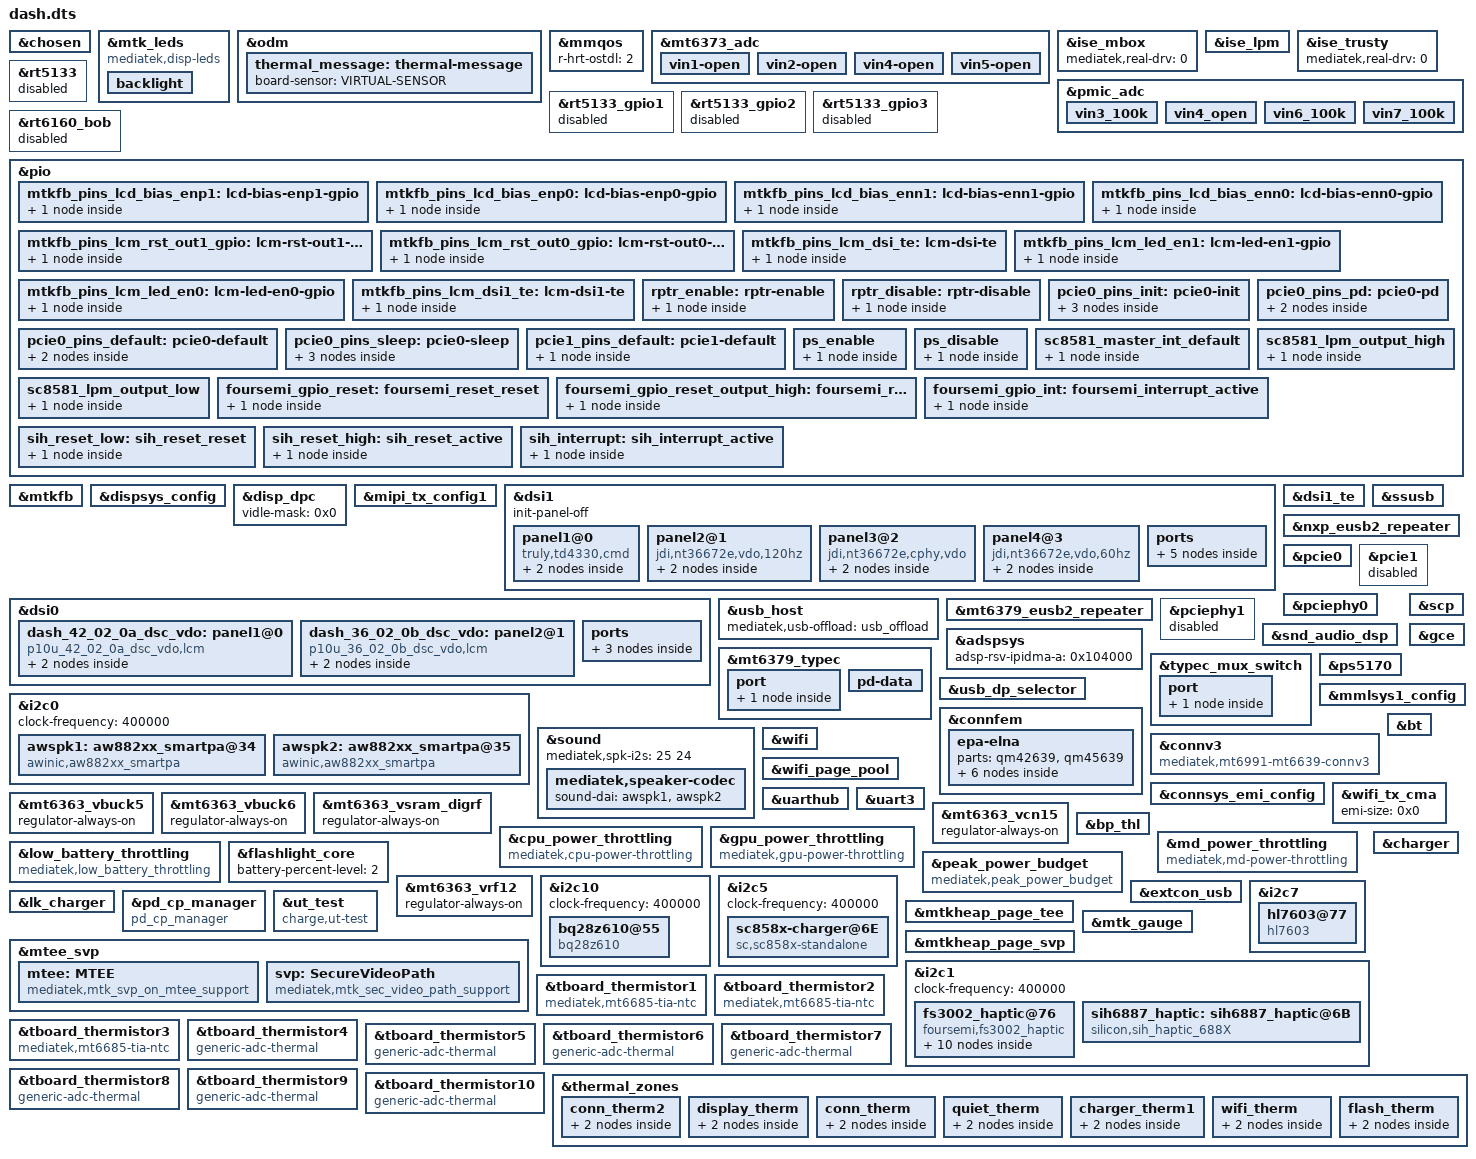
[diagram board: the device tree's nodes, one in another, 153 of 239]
// SPDX-License-Identifier: (GPL-2.0 OR MIT)
/*
 * Copyright (C) 2022 MediaTek Inc.
 */
/dts-v1/;
/plugin/;
#include <dt-bindings/clock/mt6991-clk.h>
#include <dt-bindings/interrupt-controller/arm-gic.h>
#include <dt-bindings/interrupt-controller/irq.h>
#include <dt-bindings/phy/phy.h>
#include <dt-bindings/pinctrl/mt6991-pinfunc.h>
#include <dt-bindings/power/mt6991-power.h>
#include "mediatek/dash-mt6991-common.dtsi"
#include <dt-bindings/iio/mt635x-auxadc.h>
#include <dt-bindings/thermal/thermal.h>
#include <dt-bindings/gce/mt6991-gce.h>
#include "mediatek/dash-sensor-common.dtsi"
#include "mediatek/cust_mt6991_nfc_nxp_dash.dtsi"
#include "mediatek/xiaomi_dash_t1_chip.dtsi"

&chosen {
bootargs_ext = "cpufreq.default_governor=conservative \
		rcu_nocbs=0-7";
bootargs_ext_fac = "cpufreq.default_governor=conservative \
		rcu_nocbs=0-7";
};

&mtk_leds {
	compatible = "mediatek,disp-leds";
	backlight {
		max-brightness = <16383>;
		min-brightness = <1>;
		max-hw-brightness = <16383>;
		led_mode = <4>;
		default-state = "FifteenPercent";
	};
};

&odm {
	thermal_message: thermal-message {
		board-sensor = "VIRTUAL-SENSOR";
	};
};

&mmqos {
	r-hrt-ostdl = <2>;
};

&mt6373_adc {
	vin1-open {
		channel = <AUXADC_VIN1>;
		pures = <ADC_PURES_100K>;
	};
	vin2-open {
		channel = <AUXADC_VIN2>;
		pures = <ADC_PURES_100K>;
	};
	vin4-open {
		channel = <AUXADC_VIN4>;
		pures = <ADC_PURES_100K>;
	};
	vin5-open {
		channel = <AUXADC_VIN5>;
		pures = <ADC_PURES_100K>;
	};
};

&ise_mbox {
	mediatek,real-drv = <0>;
};

&ise_lpm {
	ise-wakelock = <0>;
	ise-lpm-freerun = <0>;
	ise-lpm-deinit-bypass = <0>;
	power-domains = <&scpsys MT6991_POWER_DOMAIN_SSR>;
};

&ise_trusty {
	mediatek,real-drv = <0>;
};

&pmic_adc {
	vin3_100k {
		channel = <AUXADC_VIN3>;
		pures = <ADC_PURES_100K>;
	};
	vin4_open {
		channel = <AUXADC_VIN4>;
		pures = <ADC_PURES_100K>;
	};
	vin6_100k {
		channel = <AUXADC_VIN6>;
		pures = <ADC_PURES_100K>;
	};
	vin7_100k {
		channel = <AUXADC_VIN7>;
		pures = <ADC_PURES_100K>;
	};
};

&rt5133
{
	status = "disabled";
};
&rt5133_gpio1
{
	status = "disabled";
};
&rt5133_gpio2
{
	status = "disabled";
};
&rt5133_gpio3
{
	status = "disabled";
};
&rt6160_bob
{
	status = "disabled";
};
&pio {
	mtkfb_pins_lcd_bias_enp1: lcd-bias-enp1-gpio {
		pins-cmd-dat {
			pinmux = <PINMUX_GPIO103__FUNC_GPIO103>;
			slew-rate = <1>;
			output-high;
		};
	};

	mtkfb_pins_lcd_bias_enp0: lcd-bias-enp0-gpio {
		pins-cmd-dat {
			pinmux = <PINMUX_GPIO103__FUNC_GPIO103>;
			slew-rate = <1>;
			output-low;
		};
	};

	mtkfb_pins_lcd_bias_enn1: lcd-bias-enn1-gpio {
		pins-cmd-dat {
			pinmux = <PINMUX_GPIO103__FUNC_GPIO103>;
			slew-rate = <1>;
			output-high;
		};
	};

	mtkfb_pins_lcd_bias_enn0: lcd-bias-enn0-gpio {
		pins-cmd-dat {
			pinmux = <PINMUX_GPIO103__FUNC_GPIO103>;
			slew-rate = <1>;
			output-low;
		};
	};

	mtkfb_pins_lcm_rst_out1_gpio: lcm-rst-out1-gpio {
		pins-cmd-dat {
			pinmux = <PINMUX_GPIO90__FUNC_GPIO90>;
			slew-rate = <1>;
			output-high;
		};
	};

	mtkfb_pins_lcm_rst_out0_gpio: lcm-rst-out0-gpio {
		pins-cmd-dat {
			pinmux = <PINMUX_GPIO90__FUNC_GPIO90>;
			slew-rate = <1>;
			output-low;
		};
	};
	mtkfb_pins_lcm_dsi_te: lcm-dsi-te {
		pins-cmd-dat {
			pinmux = <PINMUX_GPIO89__FUNC_DSI_TE>;
		};
	};

	mtkfb_pins_lcm_led_en1: lcm-led-en1-gpio {
		pins-cmd-dat {
			pinmux = <PINMUX_GPIO174__FUNC_GPIO174>;
			slew-rate = <1>;
			output-high;
		};
	};

	mtkfb_pins_lcm_led_en0: lcm-led-en0-gpio {
		pins-cmd-dat {
			pinmux = <PINMUX_GPIO174__FUNC_GPIO174>;
			slew-rate = <1>;
			output-low;
		};
	};

	mtkfb_pins_lcm_dsi1_te: lcm-dsi1-te {
		pins-cmd-dat {
			pinmux = <PINMUX_GPIO6__FUNC_DSI1_TE>;
		};
	};
};

&mtkfb {
	pinctrl-names = "lcd_bias_enp1_gpio", "lcd_bias_enp0_gpio",
		"lcd_bias_enn1_gpio", "lcd_bias_enn0_gpio",
		"lcm_rst_out1_gpio", "lcm_rst_out0_gpio",
		"mode_te_te", "lcm_led_en1_gpio", "lcm_led_en0_gpio",
		"mode_te_te1";
	pinctrl-0 = <&mtkfb_pins_lcd_bias_enp1>;
	pinctrl-1 = <&mtkfb_pins_lcd_bias_enp0>;
	pinctrl-2 = <&mtkfb_pins_lcd_bias_enn1>;
	pinctrl-3 = <&mtkfb_pins_lcd_bias_enn0>;
	pinctrl-4 = <&mtkfb_pins_lcm_rst_out1_gpio>;
	pinctrl-5 = <&mtkfb_pins_lcm_rst_out0_gpio>;
	pinctrl-6 = <&mtkfb_pins_lcm_dsi_te>;
	pinctrl-7 = <&mtkfb_pins_lcm_led_en1>;
	pinctrl-8 = <&mtkfb_pins_lcm_led_en0>;
	pinctrl-9 = <&mtkfb_pins_lcm_dsi1_te>;

	status = "okay";
};

&dispsys_config {
	pinctrl-names = "mode_te_te", "mode_te_te1";
	pinctrl-0 = <&mtkfb_pins_lcm_dsi_te>;
	pinctrl-1 = <&mtkfb_pins_lcm_dsi1_te>;

	status = "okay";
//	enable-discrete-path = <1>;
//	bypass-pc-path = <0>;

	helper-name-proj = "MTK_DRM_OPT_IDLEMGR_DISABLE_ROUTINE_IRQ",
		"MTK_DRM_OPT_MML_DL_SUB_CFG_CLINET",
		"MTK_DRM_OPT_OVL_WCG",
		"MTK_DRM_OPT_OVL_WCG_BY_COLOR_MODE",
		"MTK_DRM_OPT_DSI_UNDERRUN_AEE";

	helper-value-proj = <1>, /*MTK_DRM_OPT_IDLEMGR_DISABLE_ROUTINE_IRQ*/
		<1>, /*MTK_DRM_OPT_MML_DL_SUB_CFG_CLINET*/
		<1>, /*MTK_DRM_OPT_OVL_WCG*/
		<1>, /*MTK_DRM_OPT_OVL_WCG_BY_COLOR_MODE*/
		<1>; /*MTK_DRM_OPT_DSI_UNDERRUN_AEE*/
};

&disp_dpc {
	vidle-mask = <0x0>;
};

&mipi_tx_config1 {
//	status = "okay";
};

&dsi1 {
//	status = "okay";
	#address-cells = <1>;
	#size-cells = <0>;
	init-panel-off;
	panel1@0 {
		compatible = "truly,td4330,cmd";
		reg = <0>;
		pm-enable-gpios = <&pio 215 0>;
		reset-gpios = <&pio 5 0>;
		swap-from-dts;
		lane-swap-setting = <1 2 0 3 4 2>;
		pn-swap-setting = <1 1 1 1 1 1>;
		gate-ic = <4831>;
		pinctrl-names = "default";
		port {
			panel1_in: endpoint {
				remote-endpoint = <&dsi1_out>;
			};
		};
	};
	panel2@1 {
		compatible = "jdi,nt36672e,vdo,120hz";
		reg = <1>;
		pm-enable-gpios = <&pio 215 0>;
		reset-gpios = <&pio 5 0>;
		gate-ic = <4831>;
		pinctrl-names = "default";
		port {
			panel2_in: endpoint {
				remote-endpoint = <&dsi1_out2>;
			};
		};
	};
	panel3@2 {
		compatible = "jdi,nt36672e,cphy,vdo";
		reg = <2>;
		pm-enable-gpios = <&pio 215 0>;
		reset-gpios = <&pio 5 0>;
		gate-ic = <4831>;
		pinctrl-names = "default";
		port {
			panel3_in: endpoint {
				remote-endpoint = <&dsi1_out3>;
			};
		};
	};
	panel4@3 {
		compatible = "jdi,nt36672e,vdo,60hz";
		reg = <3>;
		pm-enable-gpios = <&pio 215 0>;
		reset-gpios = <&pio 5 0>;
		gate-ic = <4831>;
		pinctrl-names = "default";
		port {
			panel4_in: endpoint {
				remote-endpoint = <&dsi1_out4>;
			};
		};
	};
	ports {
		port {
			dsi1_out: endpoint@0 {
				remote-endpoint = <&panel1_in>;
			};

			dsi1_out2: endpoint@1 {
				remote-endpoint = <&panel2_in>;
			};

			dsi1_out3: endpoint@2 {
				remote-endpoint = <&panel3_in>;
			};

			dsi1_out4: endpoint@3 {
				remote-endpoint = <&panel4_in>;
			};
		};
	};
};

&dsi1_te {
	interrupt-parent = <&pio>;
	interrupts = <6 1 6 1>;
	status = "okay";
};

&dsi0 {
	switch-spr = <1>;
	spr-ip-type = <0>;
	status = "okay";
	#address-cells = <1>;
	#size-cells = <0>;
	dash_42_02_0a_dsc_vdo:panel1@0 {
		compatible = "p10u_42_02_0a_dsc_vdo,lcm";
		reg = <0>;
		//pm-enable-gpios = <&pio 174 0>;
		reset-gpios = <&pio 90 0>;
		mi,esd-err-irq-gpio = <&pio 6 0x2002>;
		res-switch = <2>;
		//gate-ic = <4831>;
		pinctrl-names = "default";
		vcn18io-supply = <&mt6373_vcn18io>;
		vibr-supply = <&mt6373_vibr>;
		//vbuck8-supply = <&mt6373_vbuck8>;
		amoled-dvdd-supply = <&mt6363_vcn13>;
		port {
			panel_in1: endpoint {
				remote-endpoint = <&dsi_out>;
			};
		};
	};

	dash_36_02_0b_dsc_vdo:panel2@1 {
		compatible = "p10u_36_02_0b_dsc_vdo,lcm";
		reg = <1>;
		//pm-enable-gpios = <&pio 174 0>;
		reset-gpios = <&pio 90 0>;
		mi,esd-err-irq-gpio = <&pio 6 0x2002>;
		res-switch = <2>;
		//gate-ic = <4831>;
		pinctrl-names = "default";
		vcn18io-supply = <&mt6373_vcn18io>;
		vibr-supply = <&mt6373_vibr>;
		//vbuck8-supply = <&mt6373_vbuck8>;
		amoled-dvdd-supply = <&mt6363_vcn13>;
		port {
			panel_in2: endpoint {
				remote-endpoint = <&dsi_out2>;
			};
		};
	};

	ports {
		port {
			dsi_out: endpoint {
				remote-endpoint = <&panel_in1>;
			};
			dsi_out2: endpoint2 {
				remote-endpoint = <&panel_in2>;
			};
		};
	};
};

&pio {
	rptr_enable: rptr-enable {
		pins-cmd-dat {
			pinmux = <PINMUX_GPIO72__FUNC_GPIO72>;
			output-high;
		};
	};

	rptr_disable: rptr-disable {
		pins-cmd-dat {
			pinmux = <PINMUX_GPIO72__FUNC_GPIO72>;
			output-low;
		};
	};
};

&ssusb {
	mediatek,force-vbus;
	mediatek,clk-mgr;
	mediatek,usb3-drd;
	mediatek,uds = <&usb_dp_selector 19>;
	mediatek,eusb2-cm-l1 = <0x474>;
	usb-role-switch;
	status = "okay";
};

&usb_host {
	mediatek,usb-offload = <&usb_offload>;
	status = "okay";
};

&mt6379_eusb2_repeater {
	status = "okay";
	mediatek,param-override-seq =
	<
		0x1 0x6 /*mediatek,discth = <0xf>;*/
		0x2 0x4 /*mediatek,equalization = <0x4>;*/
		0x3 0x4 /*mediatek,vrt-sel = <0x2>;*/
		0x4 0x5 /*mediatek,pre-emphasis = <0x5>;*/
		0x5 0x5 /*mediatek,rx-sqth = <0x0>;*/
		0x6 0x0 /*mediatek,term-ofs = "4";*/
		0x7 0x0 /*mediatek,intr-ofs = "2";*/
	>;

	mediatek,param-override-seq-factory =
	<
		0x1 0x6 /*mediatek,discth = <0xf>;*/
		0x2 0x4 /*mediatek,equalization = <0x4>;*/
		0x3 0x4 /*mediatek,vrt-sel = <0x2>;*/
		0x4 0x5 /*mediatek,pre-emphasis = <0x5>;*/
		0x5 0x5 /*mediatek,rx-sqth = <0x0>;*/
		0x6 0x0 /*mediatek,term-ofs = "4";*/
		0x7 0x0 /*mediatek,intr-ofs = "2";*/
	>;

	mediatek,param-override-seq-carwith =
	<
		0x1 0x6 /*mediatek,discth = <0xf>;*/
		0x2 0x4 /*mediatek,equalization = <0x4>;*/
		0x3 0x4 /*mediatek,vrt-sel = <0x2>;*/
		0x4 0x5 /*mediatek,pre-emphasis = <0x5>;*/
		0x5 0x1 /*mediatek,rx-sqth = <0x0>;*/
		0x6 0x5 /*mediatek,term-ofs = "4";*/
		0x7 0x0 /*mediatek,intr-ofs = "2";*/
	>;


	mediatek,host-param-override-seq =
	<
		0x1 0x7 /*mediatek,discth = <0xf>;*/
		0x2 0x4 /*mediatek,equalization = <0x4>;*/
		0x3 0x4 /*mediatek,vrt-sel = <0x2>;*/
		0x4 0x4 /*mediatek,pre-emphasis = <0x5>;*/
		0x5 0x0 /*mediatek,rx-sqth = <0x0>;*/
		0x6 0x0 /*mediatek,term-ofs = "4";*/
		0x7 0x0 /*mediatek,intr-ofs = "2";*/
	>;

	mediatek,host-param-override-seq-factory =
	<
		0x1 0x6 /*mediatek,discth = <0xf>;*/
		0x2 0x4 /*mediatek,equalization = <0x4>;*/
		0x3 0x1 /*mediatek,vrt-sel = <0x2>;*/
		0x4 0x4 /*mediatek,pre-emphasis = <0x5>;*/
		0x5 0x5 /*mediatek,rx-sqth = <0x0>;*/
		0x6 0x0 /*mediatek,term-ofs = "4";*/
		0x7 0x0 /*mediatek,intr-ofs = "2";*/
	>;

	mediatek,host-param-override-seq-storage =
	<
		0x1 0xe /*mediatek,discth = <0xf>;*/
		0x2 0x4 /*mediatek,equalization = <0x4>;*/
		0x3 0x4 /*mediatek,vrt-sel = <0x2>;*/
		0x4 0x4 /*mediatek,pre-emphasis = <0x5>;*/
		0x5 0x0 /*mediatek,rx-sqth = <0x0>;*/
		0x6 0x0 /*mediatek,term-ofs = "4";*/
		0x7 0x0 /*mediatek,intr-ofs = "2";*/
	>;

};

&nxp_eusb2_repeater {
	pinctrl-names = "enable", "disable";
	pinctrl-0 = <&rptr_enable>;
	pinctrl-1 = <&rptr_disable>;
	status = "okay";
};

&pcie0 {
	pinctrl-names = "init", "default", "sleep", "pd";
	pinctrl-0 = <&pcie0_pins_init>;
	pinctrl-1 = <&pcie0_pins_default>;
	pinctrl-2 = <&pcie0_pins_sleep>;
	pinctrl-3 = <&pcie0_pins_pd>;
	max-link-speed = <3>;
	status = "okay";
};

&pcie1 {
	pinctrl-names = "default";
	pinctrl-0 = <&pcie1_pins_default>;
	max-link-speed = <4>;
	status = "disabled";
};

&pciephy0 {
	status = "okay";
};

&pciephy1 {
	status = "disabled";
};

/* PCIe pinmux start and falcon not use waken */
&pio {
	pcie0_pins_init: pcie0-init {
		pins-cmd-dat {
			pinmux = <PINMUX_GPIO241__FUNC_GPIO241>;
			output-low;
		};

		pins-cmd-dat1 {
			pinmux = <PINMUX_GPIO243__FUNC_GPIO243>;
			bias-pull-up;
			input-enable;
		};

		pins-cmd-dat2 {
			pinmux = <PINMUX_GPIO242__FUNC_GPIO242>;
			bias-pull-down;
			input-enable;
		};
	};

	pcie0_pins_default: pcie0-default {
		pins-cmd-dat {
			pinmux = <PINMUX_GPIO241__FUNC_PCIE_PERSTN>,
				 <PINMUX_GPIO243__FUNC_PCIE_CLKREQN>;
			bias-pull-up;
		};

		pins-cmd-dat1 {
			pinmux = <PINMUX_GPIO242__FUNC_GPIO242>;
			bias-pull-down;
			input-enable;
		};
	};

	pcie0_pins_sleep: pcie0-sleep {
		pins-cmd-dat {
			pinmux = <PINMUX_GPIO241__FUNC_GPIO241>;
			output-low;
		};

		pins-cmd-dat1 {
			pinmux = <PINMUX_GPIO243__FUNC_GPIO243>;
			bias-pull-up;
			input-enable;
		};

		pins-cmd-dat2 {
			pinmux = <PINMUX_GPIO242__FUNC_GPIO242>;
			bias-pull-down;
			input-enable;
		};
	};

	pcie0_pins_pd: pcie0-pd {
		pins-cmd-dat {
			pinmux = <PINMUX_GPIO241__FUNC_GPIO241>;
			output-low;
		};

		pins-cmd-dat1 {
			pinmux = <PINMUX_GPIO243__FUNC_GPIO243>,
				 <PINMUX_GPIO242__FUNC_GPIO242>;
			bias-pull-down;
			input-enable;
		};
	};

	pcie1_pins_default: pcie1-default {
		pins-cmd-dat {
			pinmux = <PINMUX_GPIO145__FUNC_PCIE_WAKEN_1P>,
				 <PINMUX_GPIO146__FUNC_PCIE_PERSTN_1P>,
				 <PINMUX_GPIO147__FUNC_PCIE_CLKREQN_1P>;
			bias-pull-up = <MTK_PUPD_SET_R1R0_01>;
		};
	};
};
/* PCIe pinmux end */

&snd_audio_dsp {
	swdsp-smartpa-process-enable = <0x5>;
	mtk-dsp-call-final = <0x5 0xe 0x13 0x12 0x18000>;
};

&adspsys {
	adsp-rsv-ipidma-a = <0x104000>;
};

#if 0
/* no need set here, 6686 will control elna automatically */
/* GPS GPIO standardization start */
&pio {
	gps_pins_default: gps_default {
	};
	gps_l1_lna_pins_ol: gps-l1-lna0 {
		pins-cmd-dat {
			pinmux = <PINMUX_GPIO12__FUNC_GPIO12>;
			output-low;
		};
	};
	gps_l1_lna_pins_dsp_ctrl: gps-l1-lna1 {
		pins-cmd-dat {
			pinmux = <PINMUX_GPIO12__FUNC_GPS_L1_ELNA_EN>;
		};
	};
	gps_l1_lna_pins_oh: gps-l1-lna2 {
		pins-cmd-dat {
			pinmux = <PINMUX_GPIO12__FUNC_GPIO12>;
			output-high;
		};
	};
	gps_l5_lna_pins_ol: gps-l5-lna0 {
		pins-cmd-dat {
			pinmux = <PINMUX_GPIO13__FUNC_GPIO13>;
			output-low;
		};
	};
	gps_l5_lna_pins_dsp_ctrl: gps-l5-lna1 {
		pins-cmd-dat {
			pinmux = <PINMUX_GPIO13__FUNC_GPS_L5_ELNA_EN>;
		};
	};
	gps_l5_lna_pins_oh: gps-l5-lna2 {
		pins-cmd-dat {
			pinmux = <PINMUX_GPIO13__FUNC_GPIO13>;
			output-high;
		};
	};
};
&gps {
	pinctrl-names = "default",
		"gps_l1_lna_disable",
		"gps_l1_lna_dsp_ctrl",
		"gps_l1_lna_enable",
		"gps_l5_lna_disable",
		"gps_l5_lna_dsp_ctrl",
		"gps_l5_lna_enable";
	pinctrl-0 = <&gps_pins_default>;
	pinctrl-1 = <&gps_l1_lna_pins_ol>;
	pinctrl-2 = <&gps_l1_lna_pins_dsp_ctrl>;
	pinctrl-3 = <&gps_l1_lna_pins_oh>;
	pinctrl-4 = <&gps_l5_lna_pins_ol>;
	pinctrl-5 = <&gps_l5_lna_pins_dsp_ctrl>;
	pinctrl-6 = <&gps_l5_lna_pins_oh>;
	status = "okay";
};
/* GPS GPIO standardization end */
#endif

/* usb typec mux start */
&pio {

	ps_enable: ps_enable {
		pins-cmd-dat {
			pinmux = <PINMUX_GPIO207__FUNC_GPIO207>;
			output-high;
		};
	};

	ps_disable: ps_disable {
		pins-cmd-dat {
			pinmux = <PINMUX_GPIO207__FUNC_GPIO207>;
			output-low;
		};
	};

};

&mt6379_typec {
	tcpc,en_floatgnd;
	/* 0:16x, 1:128x, 2:512x, 3:1024x */
	wd,wd0_tsleep = <1>;
	/* 0:400us, 1:1ms, 2:2ms, 3:4ms, 4:10ms, 5:40ms, 6:100ms, 7:400ms */
	wd,wd0_tdet = <3>;
	/* example wd0_tsleep = 512x, wd0_tdet = 4ms, wd0 polling time = 512*4ms */
	/* 0: Default, 1: 1.5, 2: 3.0 */
	tcpc,rp-level = <0>;

	port {
		tcpc_typec_usb: endpoint {
			remote-endpoint = <&ssusb_mux>;
		};
	};

	pd-data {
		pd,support-quick-revchg;
		pd,support-revcable;
		pd,support-direct-cap-change;
	};
};

&typec_mux_switch {
	orientation-switch;
	mode-switch;
	accessory;
	port {
		ssusb_mux: endpoint {
			remote-endpoint = <&tcpc_typec_usb>;
		};
	};
};

&ps5170 {
	pinctrl-names = "enable", "disable";
	pinctrl-0 = <&ps_enable>;
	pinctrl-1 = <&ps_disable>;
	status = "okay";
};

&usb_dp_selector {
	status = "okay";
};
/* usb typec mux end */

&scp {
	/* id, mbox, send_size*/
	send-table =
	< 0 0  11>,/* IPI_OUT_AUDIO_VOW_1 */
	//<24 0  6>,/* IPI_OUT_SCP_MPOOL_1 */
	<17 1  6>,/* IPI_OUT_LOGGER_CTRL */
	<29 1 16>,/* IPI_OUT_SENSOR_CTRL */
	<31 1  7>,/* IPI_OUT_SENSOR_NOTIFY */
	<52 1  10>,/* IPI_OUT_ELLIPTIC_ULTRA_0 */
	< 4 2  1>,/* IPI_OUT_DVFS_SET_FREQ_0 */
	< 5 2  2>,/* IPI_OUT_C_SLEEP_0 */
	< 6 2  1>,/* IPI_OUT_TEST_0 */
	//<11 2  6>,/* IPI_OUT_SCP_MPOOL_0 */
	<33 2  16>,/* IPI_OUT_SCP_CONNSYS */
	<54 2  4>,/* IPI_OUT_SCP_TP */
	< 3 3  4>,/* IPI_OUT_APCCCI_0 */
	<37 3  1>,/* IPI_OUT_SCP_AOD */
	<26 3  9>,/* IPI_OUT_AUDIO_ULTRA_SND_0 */
	<35 3  2>,/* IPI_OUT_C_SCP_HWVOTER_DEBUG */
	<45 3  1>,/* IPI_OUT_SCP_PM_NOTIFY_0 */
	<47 3  2>,/* IPI_PIN_HOST_SCP_CHRE */
	<48 3  2>,/* IPI_PIN_SCP_HOST_CHRE */
	<39 4  4>,/* IPI_OUT_AOV_SCP */
	<43 4  4>,/* IPI_OUT_NPU_SCP */
	<14 4  1>,/* IPI_OUT_DVFS_SET_FREQ_1 */
	<15 4  2>,/* IPI_OUT_C_SLEEP_1 */
	<16 4  1>,/* IPI_OUT_TEST_1 */
	<18 4  2>,/* IPI_OUT_SCPCTL_1 */
	<46 4  1>;/* IPI_OUT_SCP_PM_NOTIFY_1 */
};

&i2c0 {
	clock-frequency = <400000>;
	/* aw-top */
	awspk1: aw882xx_smartpa@34 {
		compatible = "awinic,aw882xx_smartpa";
		#sound-dai-cells = <0>;
		reg = <0x34>;
		reset-gpio = <&pio 174 0>;
		irq-gpio = <&pio 10 0x0>;
		spk-sw-gpio = <&pio 30 0x0>;
		sound-channel = <0>;
		sync-load = <1>;
		aw-re-min = <5200>;
		aw-re-max= <8000>;
		/*aw-cali-mode = "none";*/
		status = "okay";
	};
	/* aw-bot */
	awspk2: aw882xx_smartpa@35 {
		compatible = "awinic,aw882xx_smartpa";
		#sound-dai-cells = <0>;
		reg = <0x35>;
		reset-gpio = <&pio 91 0>;
		irq-gpio = <&pio 39 0x0>;
		sound-channel = <1>;
		sync-load = <1>;
		aw-re-min = <5200>;
		aw-re-max= <8000>;
		/*aw-cali-mode = "none";*/
		status = "okay";
	};
};

&sound {
	mediatek,spk-i2s = <25 24>;
	mediatek,speaker-codec {
		sound-dai = <&awspk1>, <&awspk2>;
	};
};

&gce {
	default-tokens = /bits/ 16 <CMDQ_SYNC_TOKEN_GPR_SET_0>,
			/bits/ 16 <CMDQ_SYNC_TOKEN_GPR_SET_1>,
			/bits/ 16 <CMDQ_SYNC_TOKEN_GPR_SET_2>,
			/bits/ 16 <CMDQ_SYNC_TOKEN_GPR_SET_3>,
			/bits/ 16 <CMDQ_SYNC_TOKEN_GPR_SET_4>,
			/bits/ 16 <CMDQ_SYNC_RESOURCE_WROT0>,
			/bits/ 16 <CMDQ_SYNC_RESOURCE_WROT1>,
			/bits/ 16 <CMDQ_SYNC_TOKEN_PREBUILT_MDP_LOCK>,
			/bits/ 16 <CMDQ_SYNC_TOKEN_PREBUILT_MML_LOCK>,
			/bits/ 16 <CMDQ_SYNC_TOKEN_PREBUILT_VFMT_LOCK>,
			/bits/ 16 <CMDQ_SYNC_TOKEN_PREBUILT_DISP_LOCK>,
			/bits/ 16 <CMDQ_SYNC_TOKEN_MML_MML_STOP>,
			/bits/ 16 <CMDQ_SYNC_TOKEN_MML_STREAM_CONFIG>;
	cmdq-mmp-thread-exec = <0x20030859>;
};

&mmlsys1_config {
	dl-enable;
	event-ir-disp-done = /bits/ 16 <CMDQ_SYNC_TOKEN_MML_DISP_DONE_EVENT>;
	event-mml-config = /bits/ 16 <CMDQ_SYNC_TOKEN_MML_STREAM_CONFIG>;
};

&dispsys_config {
	gce-event-names =
				"disp_mutex0_eof",
				"disp_mutex1_eof",
				"disp_token_stream_dirty0",
				"disp_token_stream_dirty1",
				"disp_token_stream_dirty3",
				"disp_wait_dsi0_te",
				"disp_wait_dsi1_te",
				"disp_wait_dsi2_te",
				"disp_token_stream_eof0",
				"disp_token_stream_eof1",
				"disp_token_stream_eof3",
				"disp_dsi0_eof",
				"disp_dsi1_eof",
				"disp_dsi2_eof",
				"disp_token_esd_eof0",
				"disp_token_esd_eof1",
				"disp_token_esd_eof3",
				"disp_rdma0_eof0",
				"disp_wdma0_eof0",
				"disp_wdma1_eof0",
				"disp_token_stream_block0",
				"disp_token_stream_block1",
				"disp_token_stream_block3",
				"disp_token_cabc_eof0",
				"disp_token_cabc_eof1",
				"disp_token_cabc_eof3",
				"disp_token_vdo_cabc_eof0",
				"disp_wdma0_eof2",
//				"disp_wait_dp_intf0_te",
				"disp_dp_intf0_eof",
				"disp_mutex2_eof",
				"disp_ovlsys_wdma2_eof2",
//				"disp_dsi0_sof0",
				"disp_token_vfp_period0",
				"disp_token_disp_va_start0",
				"disp_token_disp_va_end0",
				"disp_token_disp_va_start2",
				"disp_token_disp_va_end2",
				"disp_token_disp_te0",
				"disp_token_disp_prefetch_te0",
				"disp_gpio_te0",
				"disp_gpio_te1",
				"disp_gpio_te2",
				"disp_dsi0_targetline0",
				"disp_ovlsys_wdma0_eof0",
				"disp_ovlsys_wdma2_eof0",
				"disp_token_disp_v_idle_power_on0",
				"disp_token_disp_check_trigger_merge0",
				"dpc_disp1_prete",
				"disp_mdp_rdma0_eof3",
				"disp_y2r_eof3",
				"disp_aal0_eof",
				"disp_aal1_eof",
				"mml_disp_done_event",
				"disp_mutex0_sof0",
				"disp_ovlsys_ovl_exdma3_sof0",
				"disp_wdma4_eof0",
				"disp_ovlsys0_exdma0_eof0",
				"dispsys0_mutex0_sof",
				"mml_stream_config",
				"ovlsys0_mutex0_sof";

	gce-events =
				<&gce CMDQ_EVENT_DISP1_STREAM_DONE_ENG_EVENT0>,
				<&gce CMDQ_EVENT_DISP1_STREAM_DONE_ENG_EVENT1>,
				<&gce CMDQ_SYNC_TOKEN_CONFIG_DIRTY>,
				<&gce CMDQ_SYNC_TOKEN_CONFIG_DIRTY_1>,
				<&gce CMDQ_SYNC_TOKEN_CONFIG_DIRTY_3>,
				<&gce CMDQ_EVENT_DISP1_DISP_DSI0_ENG_EVENT1>,
				<&gce CMDQ_EVENT_DISP1_DISP_DSI1_ENG_EVENT1>,
				<&gce CMDQ_EVENT_DISP1_DISP_DSI2_ENG_EVENT1>,
				<&gce CMDQ_SYNC_TOKEN_STREAM_EOF>,
				<&gce CMDQ_SYNC_TOKEN_STREAM_EOF_1>,
				<&gce CMDQ_SYNC_TOKEN_STREAM_EOF_3>,
				<&gce CMDQ_EVENT_DISP1_FRAME_DONE_SEL1>,
				<&gce CMDQ_EVENT_DISP1_FRAME_DONE_SEL2>,
				<&gce CMDQ_EVENT_DISP1_FRAME_DONE_SEL3>,
				<&gce CMDQ_SYNC_TOKEN_ESD_EOF>,
				<&gce CMDQ_SYNC_TOKEN_ESD_EOF_1>,
				<&gce CMDQ_SYNC_TOKEN_ESD_EOF_3>,
				<&gce CMDQ_EVENT_DISP1_FRAME_DONE_SEL3>,
				<&gce CMDQ_EVENT_DISP1_FRAME_DONE_SEL4>,
				<&gce CMDQ_EVENT_DISP1_FRAME_DONE_SEL6>,
				<&gce CMDQ_SYNC_TOKEN_STREAM_BLOCK>,
				<&gce CMDQ_SYNC_TOKEN_STREAM_BLOCK_1>,
				<&gce CMDQ_SYNC_TOKEN_STREAM_BLOCK_3>,
				<&gce CMDQ_SYNC_TOKEN_CABC_EOF>,
				<&gce CMDQ_SYNC_TOKEN_CABC_EOF_1>,
				<&gce CMDQ_SYNC_TOKEN_CABC_EOF_3>,
				<&gce CMDQ_SYNC_TOKEN_VDO_MODE_CABC_EOF>,
				<&gce CMDQ_EVENT_DISP1_FRAME_DONE_SEL5>,
//				<&gce CMDQ_EVENT_DISP1_DISP_DP_INTF0_SOF>,
				<&gce CMDQ_EVENT_DISP1_FRAME_DONE_SEL0>,
				<&gce CMDQ_EVENT_DISP1_FRAME_DONE_SEL0>,
				<&gce CMDQ_EVENT_OVL1_FRAME_DONE_SEL0>,
//				<&gce CMDQ_EVENT_DISP1_DISP_DSI0_SOF>,
				<&gce CMDQ_SYNC_TOKEN_VFP_PERIOD>,
				<&gce CMDQ_SYNC_TOKEN_DISP_VA_START>,
				<&gce CMDQ_SYNC_TOKEN_DISP_VA_END>,
				<&gce CMDQ_SYNC_TOKEN_DISP_VA_START>,
				<&gce CMDQ_SYNC_TOKEN_DISP_VA_END>,
				<&gce CMDQ_SYNC_TOKEN_TE_0>,
				<&gce CMDQ_SYNC_TOKEN_PREFETCH_TE_0>,
				<&gce CMDQ_EVENT_DSI0_TE_I_DSI0_TE_I>,
				<&gce CMDQ_EVENT_DSI1_TE_I_DSI1_TE_I>,
				<&gce CMDQ_EVENT_DSI2_TE_I_DSI2_TE_I>,
				<&gce CMDQ_EVENT_DISP1_DISP_DSI0_ENG_EVENT2>,
				<&gce CMDQ_EVENT_OVL0_FRAME_DONE_SEL1>,
				<&gce CMDQ_EVENT_OVL1_FRAME_DONE_SEL1>,
				<&gce CMDQ_SYNC_TOKEN_VIDLE_POWER_ON>,
				<&gce CMDQ_SYNC_TOKEN_CHECK_TRIGGER_MERGE>,
				<&gce CMDQ_EVENT_DPC_DT_DONE6_0_MERGE>,
				<&gce CMDQ_EVENT_DISP0_FRAME_DONE_SEL0>,
				<&gce CMDQ_EVENT_DISP0_FRAME_DONE_SEL1>,
				<&gce CMDQ_EVENT_DISP0_FRAME_DONE_SEL2>,
				<&gce CMDQ_EVENT_DISP0_FRAME_DONE_SEL3>,
				<&gce CMDQ_SYNC_TOKEN_MML_DISP_DONE_EVENT>,
				<&gce CMDQ_EVENT_DISP1_STREAM_SOF0>,
				<&gce CMDQ_EVENT_OVL0_STREAM_SOF0>,
				<&gce CMDQ_EVENT_DISP1_FRAME_DONE_SEL7>,
				<&gce CMDQ_EVENT_OVL0_FRAME_DONE_SEL2>,
				<&gce CMDQ_EVENT_DISP0_STREAM_SOF0>,
				<&gce CMDQ_SYNC_TOKEN_MML_STREAM_CONFIG>,
				<&gce CMDQ_EVENT_OVL0_STREAM_SOF0>;
};

#if 0
&pdc {
	pd_vbus_upper_bound = <12000000>;
};
#endif

&connfem {
	/* Support Wifi & BT ePA/eLNA FEM on customer load */
	epa-elna {
		parts = <&qm42639 &qm45639>;
		common {
			flags-0 {
				rx-mode = [30];
				fe-ant-cnt = [81];
				fe-main-bt-share-lp2g = [80];
				fe-conn-spdt = [80];
				fe-reserved = [80];
			};
		};
		wifi {
			flags-0 {
				epa-option = [aa];
				/* open-loop; */
			};
		};
		bt {
			flags-0 {
				/* choose one of: epa-elna/epa/elna/bypass */
				epa-elna;
			};
		};
	};
};

&connv3 {
	compatible = "mediatek,mt6991-mt6639-connv3";
	pinctrl-names = "connsys-pin-pmic-en-default",
		"connsys-pin-pmic-en-set",
		"connsys-pin-pmic-en-clr",
		"connsys-pin-pmic-faultb-default",
		"connsys-pin-pmic-faultb-enable",
		"connsys-combo-gpio-init",
		"connsys-combo-gpio-pre-on",
		"connsys-combo-gpio-on",
		"connsys-pin-por-reset-trigger",
		"connsys-pin-por-reset-done";
	pinctrl-0 = <&connsys_pin_pmic_en_default>;
	pinctrl-1 = <&connsys_pin_pmic_en_set>;
	pinctrl-2 = <&connsys_pin_pmic_en_clr>;
	pinctrl-3 = <&connsys_pin_pmic_faultb_default>;
	pinctrl-4 = <&connsys_pin_pmic_faultb_enable>;
	pinctrl-5 = <&connsys_combo_gpio_init>;
	pinctrl-6 = <&connsys_combo_gpio_pre_on>;
	pinctrl-7 = <&connsys_combo_gpio_on>;
	pinctrl-8 = <&connsys_pin_por_reset_trigger>;
	pinctrl-9 = <&connsys_pin_por_reset_done>;
};

&bt {
	baudrate = <12000000>;
	flavor-bin = "new9gen2";
};

&connsys_emi_config {
	emi-layout-region =
		<0 0x00c00000>, /* 6639 WiFi MCU */
		<1 0x003c0000>, /* Connsys RO */
		<2 0x00085000>, /* Connsys RW */
		<3 0x0004b000>, /* SCP batching data */
		<4 0x00012000>, /* SCP DFD dump */
		<5 0x0000e000>, /* Reserved for alignment */
		<6 0x00040000>, /* Connsys shared data */
		<7 0x00140000>, /* GPS_EMI */
		<8 0x002fa000>, /* MNL/MPE BIN data */
		<9 0x000d6000>, /* Connsys/SCP shared */
		<10 0x000a0000>, /* WF MISC */
		<11 0x01b00000>; /* WFDMA1 */
};

&wifi {
	emi-size = <0x1b00000>;
	flavor-bin = "new9gen2";
};

&wifi_page_pool {
	cma-mem = <1>;
	emi-size = <0x5400000>;
};

&wifi_tx_cma {
	emi-size = <0x0>;
};

&bt {
	baudrate = <12000000>;
	flavor-bin = "new9gen2";
};

&uarthub {
	baud-rate = <0>; /* 0: 12m, 1: 24m */
	wakeup-mode = <0>; /* 0: sw, 1: hw */
};

&uart3 {
	clocks = <&clk104m>, <&pericfg_ao_clk CLK_PERAO_UART3_BCLK_UART>;
	hub-baud = <12000000>;
};

&mt6363_vbuck5 {
	regulator-always-on;
};

&mt6363_vbuck6 {
	regulator-always-on;
};

&mt6363_vsram_digrf {
	regulator-always-on;
};

&mt6363_vcn15 {
	regulator-always-on;
};

&bp_thl {
	max-throttle-level = <4>;
	soc-throttle-level = <0 0 1 2 2 3>, //temperature stage 0
				<0 0 1 2 2 3>, //temperature stage 1
				<0 0 1 2 2 3>, //temperature stage 2
				<0 1 1 2 2 3>, //temperature stage 3
				<1 1 1 2 3 3>, //temperature stage 4
				<1 1 2 3 4 4>, //temperature stage 5
				<1 1 2 3 4 4>; //temperature stage 6
	soc-max-stage = <5>;
	soc-limit-threshold = <80 20 15 7 5>;
	temperature-max-stage = <6>;
	temperature-stage-threshold = <50 25 10 0 0xFFFFFFF6 0xFFFFFFEC>;
};

&cpu_power_throttling{
	compatible = "mediatek,cpu-power-throttling";

	lbat-max-level = <3>;
	lbat-limit-freq-lv1 = < 1200000  1200000 1200000>;
	lbat-limit-freq-lv2 = < 1200000  1200000 1200000>;
	lbat-limit-freq-lv3 = < 330000  550000 670000>;

	oc-max-level = <2>;
	oc-limit-freq-lv1 = < 2147483647  2147483647 2147483647>;
	oc-limit-freq-lv2 = < 1200000  1700000 1900000>;

	soc-max-level = <4>;
	soc-core-active-lv1 = < 1 1 1 1 1 1 1 1 >;
	soc-core-active-lv2 = < 1 1 1 1 1 1 1 1 >;
	soc-core-active-lv3 = < 1 1 1 1 1 1 1 1 >;
	soc-core-active-lv4 = < 1 1 1 1 1 1 0 0 >;
	soc-limit-freq-lv1 = < 2147483647  2147483647 2147483647 >;
	soc-limit-freq-lv2 = < 2147483647  2147483647 2147483647 >;
	soc-limit-freq-lv3 = < 1200000 1200000 1200000>;
	soc-limit-freq-lv4 = < 1800000 900000 670000>;
};

&gpu_power_throttling{
	compatible = "mediatek,gpu-power-throttling";

	lbat-max-level = <3>;
	lbat-limit-freq-lv1 = <754000>;
	lbat-limit-freq-lv2 = <754000>;
	lbat-limit-freq-lv3 = <338000>;

	oc-max-level = <2>;
	oc-limit-freq-lv1 = <988000>;
	oc-limit-freq-lv2 = <572000>;

	soc-max-level = <4>;
	soc-limit-freq-lv1 = <2147483647>;
	soc-limit-freq-lv2 = <2147483647>;
	soc-limit-freq-lv3 = <754000>;
	soc-limit-freq-lv4 = <338000>;
};

&md_power_throttling {
		compatible = "mediatek,md-power-throttling";

		lbat-max-level = <3>;
		lbat-reduce-tx-lv1 = <0>;
		lbat-reduce-tx-lv2 = <2>;
		lbat-reduce-tx-lv3 = <2>;

		oc-max-level = <2>;
		oc-reduce-tx-lv1 = <0>;
		oc-reduce-tx-lv2 = <6>;

		soc-max-level = <0>;
};

&low_battery_throttling {
		compatible = "mediatek,low_battery_throttling";
		lvsys-thd-enable = <1>;
		vbat-thd-enable = <1>;
		bat0-thd-volts-l = <
			3100 3000 2850
			3250 3150 3000
			3300 3200 3050
			3450 3350 3200
			3570 3470 3320>;
		bat0-thd-volts-h = <
			3200 3100 3000
			3350 3250 3150
			3400 3300 3200
			3550 3450 3350
			3670 3570 3470>;
		bat1-thd-volts-l = <
			3170 3070 2920
			3230 3130 2980
			3290 3190 3040
			3400 3300 3150
			3746 3646 3496>;
		bat1-thd-volts-h = <
			3270 3170 3070
			3330 3230 3130
			3390 3290 3190
			3500 3400 3300
			3846 3746 3646>;
                bat2-thd-volts-l = <
			3150 3000 2850
			3250 3150 3000
			3350 3200 3050
			3450 3350 3200
			3550 3470 3300>;
		bat2-thd-volts-h = <
			3250 3150 3000
			3350 3250 3150
			3450 3350 3200
			3550 3450 3350
			3650 3550 3470>;
		lvsys-thd-volt-l = <2850>;
		lvsys-thd-volt-h = <3000>;
		temperature-stage-threshold = <25 10 0 0xFFFFFFF6>;

		throttle-level = <0 1 2 3>,
				<0 1 2 3>,
				<0 1 2 3>,
				<0 1 2 3>,
				<0 1 2 3>;
};

&flashlight_core {
	battery-percent-level = <2>;
};

&peak_power_budget {
	compatible = "mediatek,peak_power_budget";

	battery-circult-rdc = <28>;
	battery0-path-rac-t0 = <66>;
	battery0-path-rac-t1 = <66>;
	battery0-path-rac-t2 = <66>;
	battery0-path-rac-t3 = <66>;
	battery0-path-rac-t4 = <66>;
	battery0-path-rac-t5 = <66>;
	battery0-path-rac-t6 = <66>;
	battery1-path-rac-t0 = <63>;
	battery1-path-rac-t1 = <63>;
	battery1-path-rac-t2 = <63>;
	battery1-path-rac-t3 = <63>;
	battery1-path-rac-t4 = <63>;
	battery1-path-rac-t5 = <63>;
	battery1-path-rac-t6 = <63>;
	battery2-path-rac-t0 = <50>;
	battery2-path-rac-t1 = <50>;
	battery2-path-rac-t2 = <50>;
	battery2-path-rac-t3 = <50>;
	battery2-path-rac-t4 = <50>;
	battery2-path-rac-t5 = <50>;
	battery2-path-rac-t6 = <50>;

	system-uvlo = <2450>;

	bat-ocv-table-num = <0>;

	max-temperature-stage = <6>;
	temperature-threshold = <50 25 10 0 0xFFFFFFF6 0xFFFFFFEC>;

	soc-max-level = <4>;
	soc-hpt-ctrl-lv1 = <7>;
	soc-hpt-ctrl-lv2 = <7>;
	soc-hpt-ctrl-lv3 = <0>;
        soc-hpt-ctrl-lv4 = <0>;

	//hpt-volt = 0(2.4V), 1(2.6V) 2(2.8V) 3(3.0V) 4(3.2V)
	soc-hpt-volt-lv0 = <1>; //lv0 is high battery level setting
	soc-hpt-volt-lv1 = <1>;
	soc-hpt-volt-lv2 = <1>;
	soc-hpt-volt-lv3 = <1>;
        soc-hpt-volt-lv4 = <1>;

	//ppb-mode = 24(ppb off, hpt(HWPT) can switch scaling factor)
	//           12(ppb on,  hpt(HWPT) can switch scaling factor)
	soc-ppb-mode-lv0 = <24>; //lv0 is high battery level setting
	soc-ppb-mode-lv1 = <12>;
	soc-ppb-mode-lv2 = <12>;
	soc-ppb-mode-lv3 = <12>;
        soc-ppb-mode-lv4 = <12>;
};

&mt6363_vrf12 {
	regulator-always-on;
};

/* charger start */
&pio {
	sc8581_master_int_default: sc8581_master_int_default {
		pins-cmd-dat {
			pinmux = <PINMUX_GPIO27__FUNC_GPIO27>;
			input-enable;
		};
	};

	sc8581_lpm_output_high: sc8581_lpm_output_high {
		pins-cmd-dat {
			pinmux = <PINMUX_GPIO29__FUNC_GPIO29>;
			slew-rate = <1>;
			output-high;
		};
	};

	sc8581_lpm_output_low: sc8581_lpm_output_low {
		pins-cmd-dat {
			pinmux = <PINMUX_GPIO29__FUNC_GPIO29>;
			slew-rate = <1>;
			output-low;
		};
	};
};

&i2c10 {
	clock-frequency = <400000>;
	status = "okay";
	bq28z610@55 {
		compatible = "bq28z610";
		reg = <0x55>;
		enable_shutdown_delay;
		support_fg_fast_sample;
		normal_shutdown_vbat_1s = <3400>;
		critical_shutdown_vbat_1s = <3340>;
		report_full_rsoc_1s = <9700>;
		soc_gap_1s = <2>;
//		slave_connect_gpio = <&pio 75 0x1>;
		soc_decimal_rate = <
			0  38
			10 35
			20 33
			30 33
			40 33
			50 33
			60 33
			70 30
			80 25
			90 20
			95 10 >;
		calc_shutdown_vol_current = <300>;
		calc_shutdown_vol_soc = <9>;
		calc_shutdown_vol_after_charging_time_s = <180>;
	};
};

&i2c5 {
	clock-frequency = <400000>;
	status = "okay";
	sc858x-charger@6E{
		compatible = "sc,sc858x-standalone";
		reg = <0x6E>;
		sc,sc858x,irq-gpio = <&pio 27 IRQ_TYPE_EDGE_FALLING>;

		sc,sc858x,bat-ovp-disable = <0>;
		sc,sc858x,bat-ovp-threshold = <11>;/*4450 + val * 25*/
		sc,sc858x,usb-ovp-threshold = <11>;/*11000 + val * 1000*/
		sc,sc858x,wpc-ovp-threshold = <11>;/*11000 + val * 1000*/
		sc,sc858x,bus-ovp-threshold = <9>;/*15000 + val * 800*/
		sc,sc858x,out-ovp-threshold = <1>;/*4800 + val * 200*/
		sc,sc858x,bus-ocp-disable = <0>;
		sc,sc858x,bus-ocp-threshold = <15>;/*2500 + val * 125*/
		sc,sc858x,bus-ucp-fall-dg = <1>;/*0:8us 1:5ms 2:20ms 3:50ms*/
		sc,sc858x,pmid2out-ovp-threshold = <2>;/*200 + val * 100*/
		sc,sc858x,pmid2out-uvp-threshold = <7>;/*100 + val * 50*/
		sc,sc858x,fsw-set = <7>;/*180 + val * 60*/
		sc,sc858x,acdrv-hi-en = <1>;/*0:5V, 1:9V*/
		sc,sc858x,ss-timeout = <5>;/*0:dis 3:320ms 4:1.28s 5:5.12s 6:20.48s 7:81.92s*/
		sc,sc858x,wd-timeout = <0>;/*0:dis 1:0.2s 2:0.5s 3:1s 4:5s 5:30s*/
		sc,sc858x,mode = <1>;/*0:(4:1 chg) 1:(2:1 chg) 2:(1:1 chg) 4:(1:4 con) 5:(1:2 con) 6:(1:1 con)*/
		sc,sc858x,tsbat-flt-disable = <1>;
		sc,sc858x,tshut-disable = <1>;
		sc,sc858x,wpc-ovp-disable = <0>;
		sc,sc858x,usb-ovp-disable = <0>;
		sc,sc858x,bus-ovp-disable = <0>;
		sc,sc858x,out-ovp-disable = <0>;
		sc,sc858x,sense-r-mohm = <1>;/*0:1m  1:2m*/
		mt6375_ovp_en_gpio = <&pio 93 0x0>;

        hl7243,intr_gpio = <&pio 27 IRQ_TYPE_EDGE_FALLING>;
        charger_name = "cp_master";

        ic_role = <0>;
        hl,hl7243,vbat-ovp-dis = <0>;
        hl,hl7243,vbat-ovp = <4900>;
        hl,hl7243,vusb-ovp = <21000>;
        hl,hl7243,vwpc-ovp = <21000>;
        hl,hl7243,vbus-ovp-dis = <0>;
        hl,hl7243,vbus-ovp = <23000>;
        hl,hl7243,vout-ovp-dis = <0>;
        hl,hl7243,vout-ovp = <5400>;
        hl,hl7243,ibus-ocp-dis = <0>;
        hl,hl7243,ibus-ocp  = <4500>;
        hl,hl7243,ibus-ucp-en = <1>;
        hl,hl7243,ibus-ucp  = <200>;
        hl,hl7243,track-ov-dis = <0>;
        hl,hl7243,track-ov = <600>;
        hl,hl7243,track-uv-dis = <0>;
        hl,hl7243,track-uv = <150>;
        hl,hl7243,fsw-set = <650>;
        hl,hl7243,ss-timeout = <5>; /*3:320ms 4:1280ms 5:5120ms 6:20.48s 7:81.92s*/
        hl,hl7243,wd-timer = <0>; /*0:disable 1:0.2s 2:0.5s 3:1s 4:5s 5:30s*/
        hl,hl7243,dev_mode = <0>; /*0:4->1 1:2->1 2:1->1 4:1<-4 5:1<-2 6:1<-1*/
	};
};

&extcon_usb {
	support_quick_revchg;
	otg_boost_src = <0>; /*0:BOOST_SRC_CHARGER  1:BOOST_SRC_HBOOST  2:BOOST_SRC_EXTERNAL*/
};

&i2c7 {
	status = "ok";
	hl7603@77 {
		compatible = "hl7603";
		reg = <0x77>;
		vout_threshold = <3600>;
	};
};

&charger {
		max_charger_voltage = <12000000>;
		/* charging current */
		usb_charger_current = <500000>;
		ac_charger_current = <1600000>;
		ac_charger_input_current = <1600000>;
		charging_host_charger_current = <900000>;
		step_fallback_hyst = <125>;
		step_forward_hyst = <0>;
		jeita_fallback_hyst = <10>;
		jeita_forward_hyst = <0>;
		mt6368_moscon1_control;
		en_floatgnd;
		rust_support;
		enable_pdtest_mode = <1>;
		smart_snschg_v3_support;
		pd2_input_current = <1700000>;
		min_charger_voltage_1 = <4600000>;
		min_charger_voltage_2 = <4600000>;
		sbu_uart_en = <&pio 24 0x0>;
		ffc_high_soc = <95>;
		adapter_power = <100>;
		io-channels = <&pmic_adc AUXADC_VIN4>;
		io-channel-names = "slave_connector_auxadc";
		support_quick_revchg;
		vdm_adapter_close_vbus_support;
		step_normal_chg;
		support_disable_otg_incold;
		support_revcable;
		support_pchg_policy;
		support-direct-cap-change;

		/* CN battery paremeter */
		ffc_low_tbat = <150>;
		ffc_medium_tbat = <200>;
		ffc_warm_tbat = <350>;
		ffc_little_high_tbat = <400>;
		ffc_high_tbat = <480>;
		fv = <4530>;
		fv_normal = <4530>;
		fv_normal_warm = <4510>;
		fv_normal_high = <4500>;
		fv_ffc = <4580>;
		iterm_cold = <200>;
		iterm = <481>;
		iterm_warm = <481>;
		jeita_fcc_cfg = <(-100)	0	4000	349	349
				1	50	4000	1048	698
				51	100	3900	2619	1746
				101	120	3900	3492	2619
				121	150	3900	5238	3492
				151	480	4220	17600	17600
				481	600	4100	4365	4365>;
		jeita_fv_cfg = <(-100)	0	4540
				1	50	4550
				51	100	4550
				101	120	4550
				121	150	4550
				151	480	4580
				481	600	4100>;

		/* ATL step start */
		iterm_ffc_1_cycle_atl = <768>;
		iterm_ffc_little_warm_1_cycle_atl = <1440>;
		iterm_ffc_warm_1_cycle_atl = <2208>;
		iterm_ffc_hot_1_cycle_atl = <3168>;

		/* 15-20C cycle step */
		/* 1-100cls */
		step_chg_cfg_1_cycle_atl = <3000	3900	13095
					3901	4000	9603
					4001	4150	6984
					4151	4580	3492>;

		/* 101-300cls */
		step_chg_cfg_100_cycle_atl = <3000	3900	13095
					3901	4000	9603
					4001	4150	6984
					4151	4560	3492>;

		/* 301-800cls */
		step_chg_cfg_300_cycle_atl = <3000	3900	13095
					3901	4000	9603
					4001	4150	6984
					4151	4550	3492>;

		/* >800cls */
		step_chg_cfg_800_cycle_atl = <3000	3880	10476
					3881	4000	7682
					4001	4130	5587
					4131	4530	2793>;

		/* 20-48C cycle step */
		/* 1-100cls */
		step_chg_cfg_warm_1_cycle_atl = <3000	4200	17600
					4201	4300	12400
					4301	4400	10476
					4401	4500	8730
					4501	4580	6984>;

		/* 101-300cls */
		step_chg_cfg_warm_100_cycle_atl = <3000	4150	17600
					4151	4270	11780
					4271	4400	9952
					4401	4500	8293
					4501	4560	5587>;

		/* 301-800cls */
		step_chg_cfg_warm_300_cycle_atl = <3000	4150	17600
					4151	4270	10540
					4271	4400	8904
					4401	4500	7420
					4501	4550	5936>;

		/* >800cls */
		step_chg_cfg_warm_800_cycle_atl = <3000	4150	14080
					4151	4270	9920
					4271	4400	8380
					4401	4480	6984
					4481	4530	5587>;
		/* ATL step end */

		/* COS step start */
		iterm_ffc_1_cycle_cos = <1056>;
		iterm_ffc_little_warm_1_cycle_cos = <1344>;
		iterm_ffc_warm_1_cycle_cos = <2016>;
		iterm_ffc_hot_1_cycle_cos = <2881>;

		/* 15-20C cycle step */
		/* 1-100cls */
		step_chg_cfg_1_cycle_cos = <3000	3900	13095
					3901	4000	9603
					4001	4150	6984
					4151	4580	3492>;

		/* 101-300cls */
		step_chg_cfg_100_cycle_cos = <3000	3900	13095
					3901	4000	9603
					4001	4150	6984
					4151	4560	3492>;

		/* 301-800cls */
		step_chg_cfg_300_cycle_cos = <3000	3900	13095
					3901	4000	9603
					4001	4150	6984
					4151	4550	3492>;

		/* >800cls */
		step_chg_cfg_800_cycle_cos = <3000	3880	10476
					3881	4000	7682
					4001	4130	5587
					4131	4530	2793>;

		/* 20-48C cycle step */
		/* 1-100cls */
		step_chg_cfg_warm_1_cycle_cos = <3000	4210	17600
					4211	4310	12400
					4311	4400	10476
					4401	4500	8730
					4501	4580	6984>;

		/* 101-300cls */
		step_chg_cfg_warm_100_cycle_cos = <3000	4160	17600
					4161	4280	11780
					4281	4400	9952
					4401	4500	8293
					4501	4560	5587>;

		/* 301-800cls */
		step_chg_cfg_warm_300_cycle_cos = <3000	4160	17600
					4161	4280	10540
					4281	4400	8904
					4401	4500	7420
					4501	4550	5936>;

		/* >800cls */
		step_chg_cfg_warm_800_cycle_cos = <3000	4160	14080
					4161	4280	9920
					4281	4400	8380
					4401	4480	6984
					4481	4530	5587>;
		/* COS step end */

		/* ATL normal step start */
		/* 15-20C cycle normal step */
		/* 1-100cls */
		step_normal_chg_cfg_1_cycle_atl = <3000	3900	13095
					3901	4530	3492>;

		/* 101-300cls */
		step_normal_chg_cfg_100_cycle_atl = <3000	3900	13095
					3901	4520	3492>;

		/* 301-800cls */
		step_normal_chg_cfg_300_cycle_atl = <3000	3900	13095
					3901	4510	3492>;

		/* >800cls */
		step_normal_chg_cfg_800_cycle_atl = <3000	3900	10476
					3901	4490	2793>;

		/* 20-48C cycle normal step */
		/* 1-100cls */
		step_normal_chg_cfg_warm_1_cycle_atl = <3000	4200	17600
					4201	4530	6984>;

		/* 101-300cls */
		step_normal_chg_cfg_warm_100_cycle_atl = <3000	4150	17600
					4151	4520	6984>;

		/* 301-800cls */
		step_normal_chg_cfg_warm_300_cycle_atl = <3000	4150	17600
					4151	4510	6984>;

		/* >800cls */
		step_normal_chg_cfg_warm_800_cycle_atl = <3000	4150	14080
					4151	4490	5587>;
		/* ATL mormal step end */

		/* COS mormal step start */
		/* 15-20C cycle step */
		/* 1-100cls */
		step_normal_chg_cfg_1_cycle_cos = <3000	3900	13095
					3901	4530	3492>;

		/* 101-300cls */
		step_normal_chg_cfg_100_cycle_cos = <3000	3900	13095
					3901	4520	3492>;

		/* 301-800cls */
		step_normal_chg_cfg_300_cycle_cos = <3000	3900	13095
					3901	4510	3492>;

		/* >800cls */
		step_normal_chg_cfg_800_cycle_cos = <3000	3900	10476
					3901	4490	2793>;
		/* 20-48C cycle step */
		/* 1-100cls */
		step_normal_chg_cfg_warm_1_cycle_cos = <3000	4210	17600
					4211	4530	6984>;

		/* 101-300cls */
		step_normal_chg_cfg_warm_100_cycle_cos = <3000	4160	17600
					4161	4520	6984>;

		/* 301-800cls */
		step_normal_chg_cfg_warm_300_cycle_cos = <3000	4160	17600
					4161	4510	6984>;

		/* >800cls */
		step_normal_chg_cfg_warm_800_cycle_cos = <3000	4160	14080
					4161	4490	5587>;
		/* COS mormal step end */

		/* GL battery paremeter */
		ffc_low_tbat_gl = <150>;
		ffc_medium_tbat_gl = <200>;
		ffc_little_warm_tbat_gl = <300>;
		ffc_warm_tbat_gl = <350>;
		ffc_little_high_tbat_gl = <400>;
		ffc_high_tbat_gl = <480>;
		fv_gl = <4540>;
		fv_normal_gl = <4540>;
		fv_normal_warm_gl = <4530>;
		fv_normal_little_high_gl = <4520>;
		fv_normal_high_gl = <4510>;
		fv_ffc_gl = <4590>;
		iterm_cold_gl = <200>;
		iterm_gl = <637>;
		iterm_warm_gl = <637>;
		jeita_fcc_cfg_gl = <(-100)	0	4000	331	331
				1	50	4000	992	662
				51	100	3900	2481	1654
				101	120	3900	4962	3308
				121	150	4000	9097	9097
				151	480	4100	17600	17600
				481	600	4100	4235	4235>;
		jeita_fv_cfg_gl = <(-100)	0	4550
				1	50	4560
				51	100	4560
				101	120	4560
				121	150	4560
				151	480	4590
				481	600	4100>;

		/* ATL_GL step start */
		iterm_ffc_1_cycle_atl_gl = <1183>;
		iterm_ffc_little_warm_1_cycle_atl_gl = <1728>;
		iterm_ffc_warm_1_cycle_atl_gl = <2274>;
		iterm_ffc_little_hot_1_cycle_atl_gl = <3912>;
		iterm_ffc_hot_1_cycle_atl_gl = <5458>;

		/* 15-20C cycle step */
		/* 1-100cls */
		step_chg_cfg_1_cycle_atl_gl = <3000	3900	12405
					3901	4000	9097
					4001	4150	6616
					4151	4590	3308>;

		/* 101-300cls */
		step_chg_cfg_100_cycle_atl_gl = <3000	3900	12405
					3901	4000	9097
					4001	4150	6616
					4151	4570	3308>;

		/* 301-800cls */
		step_chg_cfg_300_cycle_atl_gl = <3000	3900	12405
					3901	4000	9097
					4001	4150	6616
					4151	4560	3308>;

		/* >800cls */
		step_chg_cfg_800_cycle_atl_gl = <3000	3880	9924
					3881	4000	7277
					4001	4130	5292
					4131	4540	2646>;

		/* 20-48C cycle step */
		/* 1-100cls */
		step_chg_cfg_warm_1_cycle_atl_gl = <3000	4100	17600
					4101	4200	12400
					4201	4400	9924
					4401	4500	8270
					4501	4590	6616>;

		/* 101-300cls */
		step_chg_cfg_warm_100_cycle_atl_gl = <3000	4050	17600
					4051	4170	11780
					4171	4400	9427
					4401	4500	7856
					4501	4570	6285>;

		/* 301-800cls */
		step_chg_cfg_warm_300_cycle_atl_gl = <3000	4050	17600
					4051	4170	10540
					4171	4400	8435
					4401	4500	7092
					4501	4560	5623>;

		/* >800cls */
		step_chg_cfg_warm_800_cycle_atl_gl = <3000	4050	14080
					4051	4170	9920
					4171	4400	7939
					4401	4480	6616
					4481	4540	5623>;
		/* ATL step end */

		/* ATl_GL normal step start */
		/* 15-20C cycle step */
		/* 1-100cls */
		step_normal_chg_cfg_1_cycle_atl_gl = <3000	3900	12405
					3901	4540	3308>;

		/* 101-300cls */
		step_normal_chg_cfg_100_cycle_atl_gl = <3000	3850	12405
					3851	4530	3308>;

		/* 301-800cls */
		step_normal_chg_cfg_300_cycle_atl_gl = <3000	3850	12405
					3851	4520	3308>;

		/* >800cls */
		step_normal_chg_cfg_800_cycle_atl_gl = <3000	3850	9924
					3851	4500	2646>;

		/* 20-48C cycle step */
		/* 1-100cls */
		step_normal_chg_cfg_warm_1_cycle_atl_gl = <3000	4100	17600
					4101	4540	6616>;

		/* 101-300cls */
		step_normal_chg_cfg_warm_100_cycle_atl_gl = <3000	4050	16720
					4051	4530	6285>;

		/* 300-800cls */
		step_normal_chg_cfg_warm_300_cycle_atl_gl = <3000	4050	14960
					4051	4520	5623>;

		/* >800cls */
		step_normal_chg_cfg_warm_800_cycle_atl_gl = <3000	4050	14080
					4051	4500	5292>;
		/* ATL normal step end */

		thermal_limit_dcp = <1900 1900 1900 1900 1900 1900 1900 1900 1900 1900 1900 1900 1500 1400 1200 1000>;
		thermal_limit_qc2 = <2500 2500 2500 2500 2500 2500 2500 2500 2500 2500 2500 2000 1500 1500 1000 500>;
		thermal_limit_qc3_18w = <2500 2500 2500 2500 2500 2500 2400 2300 2200 2100 1500 1000 800 700 600 500>;
		thermal_limit_qc3_27w = <2500 2500 2500 2500 2500 2500 2400 2300 2200 2100 1500 1000 800 700 600 500>;
		thermal_limit_qc35 = <2500 2500 2500 2500 2500 2500 2400 2300 2200 2100 1500 1000 800 700 600 500>;
		thermal_limit_pd = <17600 13500 11000 9000 8000 7000 6000 5000 4500 3500 3000 2500 2000 1500 1000 500>;

		smart_bypass_support;
		smart_bypass_entry_soc = <40>;
		smart_bypass_exit_soc = <90>;
		smart_bypass_fallback_hyst = <5>; // board_temp(0.1 degree) hyst
		smart_bypass_forward_hyst = <5>;
		smart_bypass_high_lmt_cfg = <(-100)	250	4500
				251	280	4000
				281	300	3500
				301	330	3000
				331	370	2500
				371	800	1000>;
		smart_bypass_med_lmt_cfg = <(-100)	250	17600
				251	280	10000
				281	300	8000
				301	330	6000
				331	370	5000
				371	800	2000>;
		smart_bypass_low_lmt_cfg = <(-100)	250	17600
				251	280	12000
				281	300	9000
				301	330	7000
				331	370	5000
				371	800	3000>;
};

&lk_charger {
		/* charging current */
		usb-charger-current = <500000>;
		ac-charger-current = <1800000>;
		ac-charger-input-current = <2000000>;
		non-std-ac-charger-current = <1500000>;
		charging-host-charger-current = <1500000>;
		ta-ac-charger-current = <1500000>;
		pd-charger-current = <1500000>;
		/* battery temperature protection */
		temp-t4-threshold = <60>;
		temp-t3-threshold = <45>;
		pre-charger-current = <500000>;
		fast-charge-voltage = <3100>;
		shutdown-voltage = <3200>;
		boot-battery-voltage = <3200000>;
};

&pd_cp_manager {
		compatible = "pd_cp_manager";
		fv = <4530>;
		fv_ffc = <4580>;
		max_fcc = <17600>;
		max_vbus = <20000>;
		max_ibus = <4400>;
		fcc_low_hyst = <150>;
		fcc_high_hyst = <10>;
		low_tbat = <100>;
		high_tbat = <480>;
		high_vbat = <4400>;
		high_soc = <95>;
		low_fcc = <2000>;
		cv_vbat = <4480>;
		cv_vbat_ffc = <4510>;
		cv_ibat = <1200>;
		min_pdo_vbus = <8000>;
		max_pdo_vbus = <21000>;
		mt6375_control_gpio = <&pio 93 0x0>;
		support_4_1_mode;
		support_pmic_parachg;
		switch1_1_enter = <2500>;
		switch1_1_exit = <3700>;
		switch2_1_enter = <4200>;
		switch2_1_exit = <6500>;
		pdm_ibus_gap = <600>;
		pdm_bypass_ibus_gap = <2600>;
		adapter_power = <100>;
		fv_hyst = <8>;
		support_pchg_policy;
};


&ut_test {
	compatible = "charge,ut-test";
	status = "okay";
	has-global-batt-para;

	mi,lossless_rechg_nvt_cn;
	mi,cycle_volt_nvt_cn = "0,100,4201,4301,4401,4501,4580,100,300,4151,4271,4401,4501,4560,300,800,4151,4271,4401,4501,4550,800,10000,4151,4271,4401,4481,4530";
	mi,cycle_step_curr_nvt_cn= "0,100,17600,12400,10476,8730,6984,100,300,17600,11780,9952,8293,5587,300,800,17600,10540,8904,7420,5936,800,10000,14080,9920,8380,6984,5587";
	mi,temp_term_curr_nvt_cn = "20,35,1309,35,40,2007,40,48,2880";
	mi,thermal_nvt_cn = "17600,13500,11000,9000,8000,7000,6000,5000,4000,3500,3000,2500,2000,1500,1000,500";

	mi,lossless_rechg_coslight_cn;
	mi,cycle_volt_coslight_cn = "0,100,4211,4311,4401,4501,4580,100,300,4161,4281,4401,4501,4560,300,800,4161,4281,4401,4501,4550,800,10000,4161,4281,4401,4481,4530";
	mi,cycle_step_curr_coslight_cn= "0,100,17600,12400,10476,8730,6984,100,300,17600,11780,9952,8293,5587,300,800,17600,10540,8904,7420,5936,800,10000,14080,9920,8380,6984,5587";
	mi,temp_term_curr_coslight_cn = "20,35,1222,35,40,1833,40,48,2619";
	mi,thermal_coslight_cn = "17600,13500,11000,9000,8000,7000,6000,5000,4000,3500,3000,2500,2000,1500,1000,500";

	mi,lossless_rechg_nvt_global;
	mi,cycle_volt_nvt_global = "0,100,4101,4201,4401,4501,4590,100,300,4051,4171,4401,4501,4570,300,800,4051,4171,4401,4501,4560,800,10000,4051,4171,4401,4481,4540";
	mi,cycle_step_curr_nvt_global= "0,100,17600,12400,9926,8270,6616,100,300,17600,11780,9427,7856,6285,300,800,17600,10540,8435,7092,5623,800,10000,14080,9920,7939,6616,5623";
	mi,temp_term_curr_nvt_global = "20,30,1571,30,35,2067,35,40,3556,40,48,5458";
	mi,thermal_nvt_global = "17600,13500,11000,9000,8000,7000,6000,5000,4000,3500,3000,2500,2000,1500,1000,500";
};

/* charger end */

/* svp start */
&mtee_svp {
	mtee: MTEE {
		compatible = "mediatek,mtk_svp_on_mtee_support";
	};
	svp: SecureVideoPath {
		compatible = "mediatek,mtk_sec_video_path_support";
	};
};
&mtkheap_page_tee {
	status = "ok";
};
&mtkheap_page_svp {
	status = "ok";
};
/* svp end */

#include <dash/cust.dtsi>
#include "mediatek/cust_k6991v2_connfem.dtsi"

#include "mediatek/bat_setting/mt6991p_battery_prop.dtsi"

&mtk_gauge {
	DISABLE_MTKBATTERY = <(1)>;
	FIXED_BATTERY_TEMPERATURE = <25>;

	temperature-t0 = <(50)>;
	/* Battery temperature T0 */
	temperature-t1 = <(25)>;
	/* Battery temperature T1 */
	temperature-t2 = <(10)>;
	/* Battery temperature T2 */
	temperature-t3 = <(0)>;
	/* Battery temperature T3 */
	temperature-t4 = <(-10)>;
	/* Battery temperature T4 */
	temperature-t5 = <(-20)>;
	/* Battery temperature T5 */
	active-table = <(6)>;
	#include "mediatek/dash_mt6991s_battery_table.dtsi"
};

#include "mediatek/xiaomi_dash_mt6991_touch.dtsi"
#include "mediatek/dash_mt6991_camera_v4l2.dtsi"
#include "mediatek/xiaomi_dash_mt6991_fingerprint.dtsi"
/*End of this file, DO NOT ADD ANYTHING HERE*/

&pio {
	/* Foursemi Haptic start */
	foursemi_gpio_reset: foursemi_reset_reset {
		pins_cmd_dat {
			pinmux = <PINMUX_GPIO42__FUNC_GPIO42>;
			drive-strength = <2>;
			bias-disable;
			output-low;
		};
	};
	foursemi_gpio_reset_output_high: foursemi_reset_active {
		pins_cmd_dat {
			pinmux = <PINMUX_GPIO42__FUNC_GPIO42>;
			drive-strength = <2>;
			bias-disable;
			output-high;
		};
	};
	foursemi_gpio_int: foursemi_interrupt_active {
		pins_cmd_dat {
			pinmux = <PINMUX_GPIO5__FUNC_GPIO5>;
			drive-strength = <2>;
			bias-pull-up;
			input-enable;
		};
	};

	/* SI Haptic start */
	sih_reset_low: sih_reset_reset {
		pins_cmd_dat {
			pinmux = <PINMUX_GPIO42__FUNC_GPIO42>;
			drive-strength = <2>;
			bias-disable;
			output-low;
		};
	};
	sih_reset_high: sih_reset_active {
		pins_cmd_dat {
			pinmux = <PINMUX_GPIO42__FUNC_GPIO42>;
			drive-strength = <2>;
			bias-disable;
			output-high;
		};
	};
	sih_interrupt: sih_interrupt_active {
		pins_cmd_dat {
			pinmux = <PINMUX_GPIO5__FUNC_GPIO5>;
			drive-strength = <2>;
			bias-pull-up;
			input-enable;
		};
	};
};
&i2c1 {
	clock-frequency = <400000>;
	status = "ok";
	fs3002_haptic@76 {
		compatible="foursemi,fs3002_haptic";
		reg=<0x76>;
		reset-gpio=<&pio 42 0>;//In xxxx section, please set the gpio based on the platform 
		irq-gpio=<&pio 5 0>;//In xxxx section, please set the gpio based on the platform 
		pinctrl-names="foursemi_reset_reset","foursemi_reset_active","foursemi_interrupt_active";
		pinctrl-0=<&foursemi_gpio_reset>;
		pinctrl-1=<&foursemi_gpio_reset_output_high>;
		pinctrl-2=<&foursemi_gpio_int>;
		fs3002_f0_ref=< 1700 >;
		fs3002_auto_brake=< 0 >;
		fs3002_f0_cali_mode=< 1 >;
		fs3002_cont_drv1_lvl=< 127 >;
		fs3002_cont_drv2_lvl=< 40 >;
		fs3002_cont_drv1_time=< 0 >;
		fs3002_cont_drv2_time=< 50 >;
		fs3002_cont_1_period=< 846 >;
		fs3002_brk_slopeth=< 26 >;
		fs3002_brk_gain=< 128 >;
		fs3002_brk_coefp=< 1 >;
		fs3002_brk_times=< 10 >;
		fs3002_brk_noise_gate=< 16 >;
		fs3002_brk_1_period=< 790 >;
		fs3002_brk_pgagain=< 5 >;
		fs3002_brk_margin=< 32 >;
		fs3002_play_ram_srate=< 1 >;
		fs3002_play_rtp_srate=< 1 >;
		fs3002_default_vib_mode=< 3 >;
		fs3002_vbat_mode=< 0 >;
		fs3002_lk_f0_cali=< 0 >;
		fs3002_bypass_system_gain=< 1 >;
		fs3002_f0_cali_data_mode=< 0 >;
		fs3002_lr_pgagain=< 5 >;
		fs3002_gain_adjust=< 0 >;
		fs3002_rtp_max=< 197 >;
		fs3002_rtp_time=< 20 20 20 20 20 20 20 20 20000 15000 15000 20000 25000 15000 30000 25000 20000 20000 20000 20000 20000 20000 20000 20000 20000 20000 20000 20000 20000 20000 20000 20000 20000 20000 20000 20000 20000 20000 20000 20000 20000 20000 20000 20000 20000 20000 20000 20000 20000 20000 20000 20000 20000 20000 20000 20000 20000 20000 20000 20000 20000 20000 20000 20000 20000 20000 20000 20000 20000 20000 20000 20000 20000 20000 20000 20000 20000 20000 20000 20000 20000 20000 20000 20000 20000 20000 20000 20000 20000 20000 20000 20000 20000 20000 20000 20000 20000 20000 20000 20000 20000 20000 20000 20000 20000 20000 20000 20000 20000 20000 20000 20000 20000 20000 20000 20000 20000 20000 20000 20000 20000 20000 20000 20000 20000 20000 20000 20000 20000 20000 20000 20000 20000 20000 20000 20000 20000 20000 20000 20000 20000 20000 20000 20000 20000 20000 20000 20000 20000 20000 20000 20000 20000 20000 20000 20000 20000 20000 20000 20000 20000 20000 20000 20000 20000 20000 20000 20000 20000 20000 20000 20000 20000 20000 20000 >;
		fs3002_reg_inits=< 0x217406 0xffffff 0xffffff 0xffffff 0xffffff 0xffffff 0xffffff 0xffffff 0xffffff 0xffffff >;
		fs3002_ram_id_boundary=< 10 >;
		fs3002_rtp_auto_env=< 1 >;
		fs3002_rtp_auto_size=< 1 >;
		fs3002_rtp_auto_env_mid=< 64 >;
		fs3002_rtp_auto_env_high=< 112 >;
		fs3002_lowv_ref=< 5 >;//3.9v
		fs3002_midv_ref=< 0 >;//6.5v
		fs3002_highv_ref=< 37 >;//9.7v
		fs3002_trig1_p_ref=< 33 >;//33=0x21=9.5v
		fs3002_trig1_n_ref=< 33 >;//33=0x21=9.5v
		fs3002_trig2_p_ref=< 33 >;//33=0x21=9.5v
		fs3002_trig2_n_ref=< 33 >;//33=0x21=9.5v
		fs3002_trig3_p_ref=< 33 >;//33=0x21=9.5v
		fs3002_trig3_n_ref=< 33 >;//33=0x21=9.5v
		fs3002_env_lowv=< 36 >;
		fs3002_hapstream_fre_gap=< 10 >;
		fs3002_hapstream_trans_cycles=< 4 >;
		fs3002_f0_min=< 1550 >;
		fs3002_f0_max=< 1850 >;
		fs3002_rtp_bst_sel=< 1 >;
		fs3002_trig_config=< 0 0 0 0 0 0 1 1 0 0 0 0 0 0 1 1 0 0 0 0 0 0 1 1 >;
		status = "okay";
		wf_0{
			effect-id=<0>;
			wf-vmax-mv=<3600>;
			wf-pattern=[3e 3e];
			wf-brake-pattern=[02 01 00 00];
			wf-play-rate-us=<20000>;
		};
		wf_1{
			effect-id=<1>;
			wf-vmax-mv=<3600>;
			wf-pattern=[7e 3e];
			wf-brake-pattern=[03 01 00 00];
			wf-play-rate-us=<20000>;
		};
		wf_2{
			effect-id=<2>;
			wf-vmax-mv=<3600>;
			wf-pattern=[7e 3e];
			wf-brake-pattern=[02 01 00 00];
			wf-play-rate-us=<20000>;
		};
		wf_3{
			effect-id=<3>;
			wf-vmax-mv=<3600>;
			wf-pattern=[3e 3e];
			wf-brake-pattern=[02 01 00 00];
			wf-play-rate-us=<20000>;
		};
		wf_4{
			effect-id=<4>;
			wf-vmax-mv=<3600>;
			wf-pattern=[3e 3e];
			wf-brake-pattern=[02 01 00 00];
			wf-play-rate-us=<28000>;
		};
		wf_5{
			effect-id=<5>;
			wf-vmax-mv=<3600>;
			wf-pattern=[7e 7e 7e];
			wf-brake-pattern=[03 03 01 00];
			wf-play-rate-us=<20000>;
		};
		wf_6{
			effect-id=<6>;
			wf-vmax-mv=<3600>;
			wf-pattern=[3e 3e];
			wf-brake-pattern=[02 01 00 00];
			wf-play-rate-us=<20000>;
		};
		wf_7{
			effect-id=<7>;
			wf-vmax-mv=<3600>;
			wf-pattern=[3e 3e];
			wf-brake-pattern=[02 01 00 00];
			wf-play-rate-us=<20000>;
		};
		wf_8{
			effect-id=<8>;
			wf-vmax-mv=<3600>;
			wf-pattern=[3e 3e];
			wf-brake-pattern=[02 01 00 00];
			wf-play-rate-us=<20000>;
		};
		wf_9{
			effect-id=<9>;
			wf-vmax-mv=<3600>;
			wf-pattern=[3e 3e];
			wf-brake-pattern=[02 01 00 00];
			wf-play-rate-us=<20000>;
		};
	};
	/* Foursemi Haptic */

	/* SI Haptic */
	sih6887_haptic:sih6887_haptic@6B{
		compatible = "silicon,sih_haptic_688X";
		reg = <0x6B>;
		reset-gpio = <&pio 42 0>;
		irq-gpio = <&pio 5 0>;
		interrupt=<26 1>;
		pinctrl-names = "sih_reset_reset","sih_reset_active","sih_interrupt_active";
		pinctrl-0 = <&sih_reset_low>;
		pinctrl-1 = <&sih_reset_high>;
		pinctrl-2 = <&sih_interrupt>;
		lra_name = "0809";
		vib_effect_id_boundary = < 10 >;
		vib_effect_max = < 197 >;
		vib_f0_pre = < 1700 >;
		loop_voltage = < 3960 >;
		vib_bst_vol_default = < 100 >;
		lp_pvdds = < 65 70 75 100 >;
		lp_ipeaks = < 45 45 45 45 >;
    };
	/* SI Haptic */
};

&tboard_thermistor1 {
		compatible = "mediatek,mt6685-tia-ntc";
		#thermal-sensor-cells = <0>;
		reg = <0 0x1c01d128 0 0x4>; /* TIA DATA T0 */
		temperature-lookup-table =
			<(-40000) 4397119>,
			<(-39000) 4092874>,
			<(-38000) 3811717>,
			<(-37000) 3551749>,
			<(-36000) 3311236>,
			<(-35000) 3088599>,
			<(-34000) 2882396>,
			<(-33000) 2691310>,
			<(-32000) 2514137>,
			<(-31000) 2349778>,
			<(-30000) 2197225>,
			<(-29000) 2055558>,
			<(-28000) 1923932>,
			<(-27000) 1801573>,
			<(-26000) 1687773>,
			<(-25000) 1581881>,
			<(-24000) 1483100>,
			<(-23000) 1391113>,
			<(-22000) 1305413>,
			<(-21000) 1225531>,
			<(-20000) 1151037>,
			<(-19000) 1081535>,
			<(-18000) 1016661>,
			<(-17000) 956080>,
			<(-16000) 899481>,
			<(-15000) 846579>,
			<(-14000) 797111>,
			<(-13000) 750834>,
			<(-12000) 707524>,
			<(-11000) 666972>,
			<(-10000) 628988>,
			<(-9000) 593342>,
			<(-8000) 559931>,
			<(-7000) 528602>,
			<(-6000) 499212>,
			<(-5000) 471632>,
			<(-4000) 445772>,
			<(-3000) 421480>,
			<(-2000) 398652>,
			<(-1000) 377193>,
			<0 357012>,
			<1000 338006>,
			<2000 320122>,
			<3000 303287>,
			<4000 287434>,
			<5000 272500>,
			<6000 258426>,
			<7000 245160>,
			<8000 232649>,
			<9000 220847>,
			<10000 209710>,
			<11000 199196>,
			<12000 189268>,
			<13000 179890>,
			<14000 171027>,
			<15000 162651>,
			<16000 154726>,
			<17000 147232>,
			<18000 140142>,
			<19000 133432>,
			<20000 127080>,
			<21000 121066>,
			<22000 115368>,
			<23000 109970>,
			<24000 104852>,
			<25000 100000>,
			<26000 95398>,
			<27000 91032>,
			<28000 86889>,
			<29000 82956>,
			<30000 79222>,
			<31000 75675>,
			<32000 72306>,
			<33000 69104>,
			<34000 66061>,
			<35000 63167>,
			<36000 60415>,
			<37000 57797>,
			<38000 55306>,
			<39000 52934>,
			<40000 50677>,
			<41000 48528>,
			<42000 46482>,
			<43000 44533>,
			<44000 42675>,
			<45000 40904>,
			<46000 39213>,
			<47000 37601>,
			<48000 36063>,
			<49000 34595>,
			<50000 33195>,
			<51000 31859>,
			<52000 30584>,
			<53000 29366>,
			<54000 28203>,
			<55000 27091>,
			<56000 26028>,
			<57000 25013>,
			<58000 24042>,
			<59000 23113>,
			<60000 22224>,
			<61000 21374>,
			<62000 20560>,
			<63000 19782>,
			<64000 19036>,
			<65000 18322>,
			<66000 17640>,
			<67000 16986>,
			<68000 16360>,
			<69000 15759>,
			<70000 15184>,
			<71000 14631>,
			<72000 14100>,
			<73000 13591>,
			<74000 13103>,
			<75000 12635>,
			<76000 12187>,
			<77000 11756>,
			<78000 11343>,
			<79000 10946>,
			<80000 10565>,
			<81000 10199>,
			<82000 9847>,
			<83000 9509>,
			<84000 9184>,
			<85000 8872>,
			<86000 8572>,
			<87000 8283>,
			<88000 8005>,
			<89000 7738>,
			<90000 7481>,
			<91000 7234>,
			<92000 6997>,
			<93000 6769>,
			<94000 6548>,
			<95000 6337>,
			<96000 6132>,
			<97000 5934>,
			<98000 5744>,
			<99000 5561>,
			<100000 5384>,
			<101000 5214>,
			<102000 5051>,
			<103000 4893>,
			<104000 4741>,
			<105000 4594>,
			<106000 4453>,
			<107000 4316>,
			<108000 4184>,
			<109000 4057>,
			<110000 3934>,
			<111000 3816>,
			<112000 3701>,
			<113000 3591>,
			<114000 3484>,
			<115000 3380>,
			<116000 3281>,
			<117000 3185>,
			<118000 3093>,
			<119000 3003>,
			<120000 2916>,
			<121000 2832>,
			<122000 2751>,
			<123000 2672>,
			<124000 2596>,
			<125000 2522>;
	};

	&tboard_thermistor2 {
		compatible = "mediatek,mt6685-tia-ntc";
		#thermal-sensor-cells = <0>;
		reg = <0 0x1c01d12c 0 0x4>; /* TIA DATA T1 */
		temperature-lookup-table =
			<(-40000) 4397119>,
			<(-39000) 4092874>,
			<(-38000) 3811717>,
			<(-37000) 3551749>,
			<(-36000) 3311236>,
			<(-35000) 3088599>,
			<(-34000) 2882396>,
			<(-33000) 2691310>,
			<(-32000) 2514137>,
			<(-31000) 2349778>,
			<(-30000) 2197225>,
			<(-29000) 2055558>,
			<(-28000) 1923932>,
			<(-27000) 1801573>,
			<(-26000) 1687773>,
			<(-25000) 1581881>,
			<(-24000) 1483100>,
			<(-23000) 1391113>,
			<(-22000) 1305413>,
			<(-21000) 1225531>,
			<(-20000) 1151037>,
			<(-19000) 1081535>,
			<(-18000) 1016661>,
			<(-17000) 956080>,
			<(-16000) 899481>,
			<(-15000) 846579>,
			<(-14000) 797111>,
			<(-13000) 750834>,
			<(-12000) 707524>,
			<(-11000) 666972>,
			<(-10000) 628988>,
			<(-9000) 593342>,
			<(-8000) 559931>,
			<(-7000) 528602>,
			<(-6000) 499212>,
			<(-5000) 471632>,
			<(-4000) 445772>,
			<(-3000) 421480>,
			<(-2000) 398652>,
			<(-1000) 377193>,
			<0 357012>,
			<1000 338006>,
			<2000 320122>,
			<3000 303287>,
			<4000 287434>,
			<5000 272500>,
			<6000 258426>,
			<7000 245160>,
			<8000 232649>,
			<9000 220847>,
			<10000 209710>,
			<11000 199196>,
			<12000 189268>,
			<13000 179890>,
			<14000 171027>,
			<15000 162651>,
			<16000 154726>,
			<17000 147232>,
			<18000 140142>,
			<19000 133432>,
			<20000 127080>,
			<21000 121066>,
			<22000 115368>,
			<23000 109970>,
			<24000 104852>,
			<25000 100000>,
			<26000 95398>,
			<27000 91032>,
			<28000 86889>,
			<29000 82956>,
			<30000 79222>,
			<31000 75675>,
			<32000 72306>,
			<33000 69104>,
			<34000 66061>,
			<35000 63167>,
			<36000 60415>,
			<37000 57797>,
			<38000 55306>,
			<39000 52934>,
			<40000 50677>,
			<41000 48528>,
			<42000 46482>,
			<43000 44533>,
			<44000 42675>,
			<45000 40904>,
			<46000 39213>,
			<47000 37601>,
			<48000 36063>,
			<49000 34595>,
			<50000 33195>,
			<51000 31859>,
			<52000 30584>,
			<53000 29366>,
			<54000 28203>,
			<55000 27091>,
			<56000 26028>,
			<57000 25013>,
			<58000 24042>,
			<59000 23113>,
			<60000 22224>,
			<61000 21374>,
			<62000 20560>,
			<63000 19782>,
			<64000 19036>,
			<65000 18322>,
			<66000 17640>,
			<67000 16986>,
			<68000 16360>,
			<69000 15759>,
			<70000 15184>,
			<71000 14631>,
			<72000 14100>,
			<73000 13591>,
			<74000 13103>,
			<75000 12635>,
			<76000 12187>,
			<77000 11756>,
			<78000 11343>,
			<79000 10946>,
			<80000 10565>,
			<81000 10199>,
			<82000 9847>,
			<83000 9509>,
			<84000 9184>,
			<85000 8872>,
			<86000 8572>,
			<87000 8283>,
			<88000 8005>,
			<89000 7738>,
			<90000 7481>,
			<91000 7234>,
			<92000 6997>,
			<93000 6769>,
			<94000 6548>,
			<95000 6337>,
			<96000 6132>,
			<97000 5934>,
			<98000 5744>,
			<99000 5561>,
			<100000 5384>,
			<101000 5214>,
			<102000 5051>,
			<103000 4893>,
			<104000 4741>,
			<105000 4594>,
			<106000 4453>,
			<107000 4316>,
			<108000 4184>,
			<109000 4057>,
			<110000 3934>,
			<111000 3816>,
			<112000 3701>,
			<113000 3591>,
			<114000 3484>,
			<115000 3380>,
			<116000 3281>,
			<117000 3185>,
			<118000 3093>,
			<119000 3003>,
			<120000 2916>,
			<121000 2832>,
			<122000 2751>,
			<123000 2672>,
			<124000 2596>,
			<125000 2522>;
	};

	&tboard_thermistor3 {
		compatible = "mediatek,mt6685-tia-ntc";
		#thermal-sensor-cells = <0>;
		reg = <0 0x1c01d130 0 0x4>; /* TIA DATA T2 */
		temperature-lookup-table =
			<(-40000) 4397119>,
			<(-39000) 4092874>,
			<(-38000) 3811717>,
			<(-37000) 3551749>,
			<(-36000) 3311236>,
			<(-35000) 3088599>,
			<(-34000) 2882396>,
			<(-33000) 2691310>,
			<(-32000) 2514137>,
			<(-31000) 2349778>,
			<(-30000) 2197225>,
			<(-29000) 2055558>,
			<(-28000) 1923932>,
			<(-27000) 1801573>,
			<(-26000) 1687773>,
			<(-25000) 1581881>,
			<(-24000) 1483100>,
			<(-23000) 1391113>,
			<(-22000) 1305413>,
			<(-21000) 1225531>,
			<(-20000) 1151037>,
			<(-19000) 1081535>,
			<(-18000) 1016661>,
			<(-17000) 956080>,
			<(-16000) 899481>,
			<(-15000) 846579>,
			<(-14000) 797111>,
			<(-13000) 750834>,
			<(-12000) 707524>,
			<(-11000) 666972>,
			<(-10000) 628988>,
			<(-9000) 593342>,
			<(-8000) 559931>,
			<(-7000) 528602>,
			<(-6000) 499212>,
			<(-5000) 471632>,
			<(-4000) 445772>,
			<(-3000) 421480>,
			<(-2000) 398652>,
			<(-1000) 377193>,
			<0 357012>,
			<1000 338006>,
			<2000 320122>,
			<3000 303287>,
			<4000 287434>,
			<5000 272500>,
			<6000 258426>,
			<7000 245160>,
			<8000 232649>,
			<9000 220847>,
			<10000 209710>,
			<11000 199196>,
			<12000 189268>,
			<13000 179890>,
			<14000 171027>,
			<15000 162651>,
			<16000 154726>,
			<17000 147232>,
			<18000 140142>,
			<19000 133432>,
			<20000 127080>,
			<21000 121066>,
			<22000 115368>,
			<23000 109970>,
			<24000 104852>,
			<25000 100000>,
			<26000 95398>,
			<27000 91032>,
			<28000 86889>,
			<29000 82956>,
			<30000 79222>,
			<31000 75675>,
			<32000 72306>,
			<33000 69104>,
			<34000 66061>,
			<35000 63167>,
			<36000 60415>,
			<37000 57797>,
			<38000 55306>,
			<39000 52934>,
			<40000 50677>,
			<41000 48528>,
			<42000 46482>,
			<43000 44533>,
			<44000 42675>,
			<45000 40904>,
			<46000 39213>,
			<47000 37601>,
			<48000 36063>,
			<49000 34595>,
			<50000 33195>,
			<51000 31859>,
			<52000 30584>,
			<53000 29366>,
			<54000 28203>,
			<55000 27091>,
			<56000 26028>,
			<57000 25013>,
			<58000 24042>,
			<59000 23113>,
			<60000 22224>,
			<61000 21374>,
			<62000 20560>,
			<63000 19782>,
			<64000 19036>,
			<65000 18322>,
			<66000 17640>,
			<67000 16986>,
			<68000 16360>,
			<69000 15759>,
			<70000 15184>,
			<71000 14631>,
			<72000 14100>,
			<73000 13591>,
			<74000 13103>,
			<75000 12635>,
			<76000 12187>,
			<77000 11756>,
			<78000 11343>,
			<79000 10946>,
			<80000 10565>,
			<81000 10199>,
			<82000 9847>,
			<83000 9509>,
			<84000 9184>,
			<85000 8872>,
			<86000 8572>,
			<87000 8283>,
			<88000 8005>,
			<89000 7738>,
			<90000 7481>,
			<91000 7234>,
			<92000 6997>,
			<93000 6769>,
			<94000 6548>,
			<95000 6337>,
			<96000 6132>,
			<97000 5934>,
			<98000 5744>,
			<99000 5561>,
			<100000 5384>,
			<101000 5214>,
			<102000 5051>,
			<103000 4893>,
			<104000 4741>,
			<105000 4594>,
			<106000 4453>,
			<107000 4316>,
			<108000 4184>,
			<109000 4057>,
			<110000 3934>,
			<111000 3816>,
			<112000 3701>,
			<113000 3591>,
			<114000 3484>,
			<115000 3380>,
			<116000 3281>,
			<117000 3185>,
			<118000 3093>,
			<119000 3003>,
			<120000 2916>,
			<121000 2832>,
			<122000 2751>,
			<123000 2672>,
			<124000 2596>,
			<125000 2522>;
	};

	&tboard_thermistor4 {
		compatible = "generic-adc-thermal";
		#thermal-sensor-cells = <0>;
		io-channels = <&pmic_adc AUXADC_VIN3>;
		io-channel-names = "sensor-channel";
		temperature-lookup-table =
			<(-40000) 1799>,
			<(-39000) 1796>,
			<(-38000) 1792>,
			<(-37000) 1789>,
			<(-36000) 1786>,
			<(-35000) 1782>,
			<(-34000) 1778>,
			<(-33000) 1774>,
			<(-32000) 1769>,
			<(-31000) 1764>,
			<(-30000) 1759>,
			<(-29000) 1754>,
			<(-28000) 1749>,
			<(-27000) 1743>,
			<(-26000) 1737>,
			<(-25000) 1730>,
			<(-24000) 1723>,
			<(-23000) 1716>,
			<(-22000) 1709>,
			<(-21000) 1701>,
			<(-20000) 1692>,
			<(-19000) 1684>,
			<(-18000) 1675>,
			<(-17000) 1665>,
			<(-16000) 1655>,
			<(-15000) 1645>,
			<(-14000) 1634>,
			<(-13000) 1623>,
			<(-12000) 1612>,
			<(-11000) 1600>,
			<(-10000) 1587>,
			<(-9000) 1574>,
			<(-8000) 1561>,
			<(-7000) 1547>,
			<(-6000) 1532>,
			<(-5000) 1518>,
			<(-4000) 1502>,
			<(-3000) 1487>,
			<(-2000) 1471>,
			<(-1000) 1454>,
			<0 1437>,
			<1000 1419>,
			<2000 1402>,
			<3000 1383>,
			<4000 1365>,
			<5000 1346>,
			<6000 1326>,
			<7000 1306>,
			<8000 1286>,
			<9000 1266>,
			<10000 1245>,
			<11000 1225>,
			<12000 1203>,
			<13000 1182>,
			<14000 1161>,
			<15000 1139>,
			<16000 1117>,
			<17000 1095>,
			<18000 1073>,
			<19000 1051>,
			<20000 1029>,
			<21000 1007>,
			<22000 985>,
			<23000 963>,
			<24000 941>,
			<25000 920>,
			<26000 898>,
			<27000 876>,
			<28000 855>,
			<29000 834>,
			<30000 813>,
			<31000 792>,
			<32000 772>,
			<33000 751>,
			<34000 731>,
			<35000 712>,
			<36000 692>,
			<37000 673>,
			<38000 655>,
			<39000 636>,
			<40000 618>,
			<41000 601>,
			<42000 583>,
			<43000 566>,
			<44000 550>,
			<45000 534>,
			<46000 518>,
			<47000 502>,
			<48000 487>,
			<49000 472>,
			<50000 458>,
			<51000 444>,
			<52000 430>,
			<53000 417>,
			<54000 404>,
			<55000 392>,
			<56000 380>,
			<57000 368>,
			<58000 356>,
			<59000 345>,
			<60000 334>,
			<61000 324>,
			<62000 313>,
			<63000 303>,
			<64000 294>,
			<65000 284>,
			<66000 275>,
			<67000 267>,
			<68000 258>,
			<69000 250>,
			<70000 242>,
			<71000 234>,
			<72000 227>,
			<73000 220>,
			<74000 213>,
			<75000 206>,
			<76000 199>,
			<77000 193>,
			<78000 187>,
			<79000 181>,
			<80000 175>,
			<81000 170>,
			<82000 164>,
			<83000 159>,
			<84000 154>,
			<85000 149>,
			<86000 145>,
			<87000 140>,
			<88000 136>,
			<89000 132>,
			<90000 128>,
			<91000 124>,
			<92000 120>,
			<93000 116>,
			<94000 113>,
			<95000 109>,
			<96000 106>,
			<97000 103>,
			<98000 99>,
			<99000 96>,
			<100000 94>,
			<101000 91>,
			<102000 88>,
			<103000 85>,
			<104000 83>,
			<105000 80>,
			<106000 78>,
			<107000 76>,
			<108000 73>,
			<109000 71>,
			<110000 69>,
			<111000 67>,
			<112000 65>,
			<113000 63>,
			<114000 61>,
			<115000 60>,
			<116000 58>,
			<117000 56>,
			<118000 55>,
			<119000 53>,
			<120000 52>,
			<121000 50>,
			<122000 49>,
			<123000 47>,
			<124000 46>,
			<125000 45>;
	};

	&tboard_thermistor5 {
		compatible = "generic-adc-thermal";
		#thermal-sensor-cells = <0>;
		io-channels = <&pmic_adc AUXADC_VIN6>;
		io-channel-names = "sensor-channel";
		temperature-lookup-table =
			<(-40000) 1799>,
			<(-39000) 1796>,
			<(-38000) 1792>,
			<(-37000) 1789>,
			<(-36000) 1786>,
			<(-35000) 1782>,
			<(-34000) 1778>,
			<(-33000) 1774>,
			<(-32000) 1769>,
			<(-31000) 1764>,
			<(-30000) 1759>,
			<(-29000) 1754>,
			<(-28000) 1749>,
			<(-27000) 1743>,
			<(-26000) 1737>,
			<(-25000) 1730>,
			<(-24000) 1723>,
			<(-23000) 1716>,
			<(-22000) 1709>,
			<(-21000) 1701>,
			<(-20000) 1692>,
			<(-19000) 1684>,
			<(-18000) 1675>,
			<(-17000) 1665>,
			<(-16000) 1655>,
			<(-15000) 1645>,
			<(-14000) 1634>,
			<(-13000) 1623>,
			<(-12000) 1612>,
			<(-11000) 1600>,
			<(-10000) 1587>,
			<(-9000) 1574>,
			<(-8000) 1561>,
			<(-7000) 1547>,
			<(-6000) 1532>,
			<(-5000) 1518>,
			<(-4000) 1502>,
			<(-3000) 1487>,
			<(-2000) 1471>,
			<(-1000) 1454>,
			<0 1437>,
			<1000 1419>,
			<2000 1402>,
			<3000 1383>,
			<4000 1365>,
			<5000 1346>,
			<6000 1326>,
			<7000 1306>,
			<8000 1286>,
			<9000 1266>,
			<10000 1245>,
			<11000 1225>,
			<12000 1203>,
			<13000 1182>,
			<14000 1161>,
			<15000 1139>,
			<16000 1117>,
			<17000 1095>,
			<18000 1073>,
			<19000 1051>,
			<20000 1029>,
			<21000 1007>,
			<22000 985>,
			<23000 963>,
			<24000 941>,
			<25000 920>,
			<26000 898>,
			<27000 876>,
			<28000 855>,
			<29000 834>,
			<30000 813>,
			<31000 792>,
			<32000 772>,
			<33000 751>,
			<34000 731>,
			<35000 712>,
			<36000 692>,
			<37000 673>,
			<38000 655>,
			<39000 636>,
			<40000 618>,
			<41000 601>,
			<42000 583>,
			<43000 566>,
			<44000 550>,
			<45000 534>,
			<46000 518>,
			<47000 502>,
			<48000 487>,
			<49000 472>,
			<50000 458>,
			<51000 444>,
			<52000 430>,
			<53000 417>,
			<54000 404>,
			<55000 392>,
			<56000 380>,
			<57000 368>,
			<58000 356>,
			<59000 345>,
			<60000 334>,
			<61000 324>,
			<62000 313>,
			<63000 303>,
			<64000 294>,
			<65000 284>,
			<66000 275>,
			<67000 267>,
			<68000 258>,
			<69000 250>,
			<70000 242>,
			<71000 234>,
			<72000 227>,
			<73000 220>,
			<74000 213>,
			<75000 206>,
			<76000 199>,
			<77000 193>,
			<78000 187>,
			<79000 181>,
			<80000 175>,
			<81000 170>,
			<82000 164>,
			<83000 159>,
			<84000 154>,
			<85000 149>,
			<86000 145>,
			<87000 140>,
			<88000 136>,
			<89000 132>,
			<90000 128>,
			<91000 124>,
			<92000 120>,
			<93000 116>,
			<94000 113>,
			<95000 109>,
			<96000 106>,
			<97000 103>,
			<98000 99>,
			<99000 96>,
			<100000 94>,
			<101000 91>,
			<102000 88>,
			<103000 85>,
			<104000 83>,
			<105000 80>,
			<106000 78>,
			<107000 76>,
			<108000 73>,
			<109000 71>,
			<110000 69>,
			<111000 67>,
			<112000 65>,
			<113000 63>,
			<114000 61>,
			<115000 60>,
			<116000 58>,
			<117000 56>,
			<118000 55>,
			<119000 53>,
			<120000 52>,
			<121000 50>,
			<122000 49>,
			<123000 47>,
			<124000 46>,
			<125000 45>;
	};

	&tboard_thermistor6 {
		compatible = "generic-adc-thermal";
		#thermal-sensor-cells = <0>;
		io-channels = <&pmic_adc AUXADC_VIN7>;
		io-channel-names = "sensor-channel";
		temperature-lookup-table =
			<(-40000) 1799>,
			<(-39000) 1796>,
			<(-38000) 1792>,
			<(-37000) 1789>,
			<(-36000) 1786>,
			<(-35000) 1782>,
			<(-34000) 1778>,
			<(-33000) 1774>,
			<(-32000) 1769>,
			<(-31000) 1764>,
			<(-30000) 1759>,
			<(-29000) 1754>,
			<(-28000) 1749>,
			<(-27000) 1743>,
			<(-26000) 1737>,
			<(-25000) 1730>,
			<(-24000) 1723>,
			<(-23000) 1716>,
			<(-22000) 1709>,
			<(-21000) 1701>,
			<(-20000) 1692>,
			<(-19000) 1684>,
			<(-18000) 1675>,
			<(-17000) 1665>,
			<(-16000) 1655>,
			<(-15000) 1645>,
			<(-14000) 1634>,
			<(-13000) 1623>,
			<(-12000) 1612>,
			<(-11000) 1600>,
			<(-10000) 1587>,
			<(-9000) 1574>,
			<(-8000) 1561>,
			<(-7000) 1547>,
			<(-6000) 1532>,
			<(-5000) 1518>,
			<(-4000) 1502>,
			<(-3000) 1487>,
			<(-2000) 1471>,
			<(-1000) 1454>,
			<0 1437>,
			<1000 1419>,
			<2000 1402>,
			<3000 1383>,
			<4000 1365>,
			<5000 1346>,
			<6000 1326>,
			<7000 1306>,
			<8000 1286>,
			<9000 1266>,
			<10000 1245>,
			<11000 1225>,
			<12000 1203>,
			<13000 1182>,
			<14000 1161>,
			<15000 1139>,
			<16000 1117>,
			<17000 1095>,
			<18000 1073>,
			<19000 1051>,
			<20000 1029>,
			<21000 1007>,
			<22000 985>,
			<23000 963>,
			<24000 941>,
			<25000 920>,
			<26000 898>,
			<27000 876>,
			<28000 855>,
			<29000 834>,
			<30000 813>,
			<31000 792>,
			<32000 772>,
			<33000 751>,
			<34000 731>,
			<35000 712>,
			<36000 692>,
			<37000 673>,
			<38000 655>,
			<39000 636>,
			<40000 618>,
			<41000 601>,
			<42000 583>,
			<43000 566>,
			<44000 550>,
			<45000 534>,
			<46000 518>,
			<47000 502>,
			<48000 487>,
			<49000 472>,
			<50000 458>,
			<51000 444>,
			<52000 430>,
			<53000 417>,
			<54000 404>,
			<55000 392>,
			<56000 380>,
			<57000 368>,
			<58000 356>,
			<59000 345>,
			<60000 334>,
			<61000 324>,
			<62000 313>,
			<63000 303>,
			<64000 294>,
			<65000 284>,
			<66000 275>,
			<67000 267>,
			<68000 258>,
			<69000 250>,
			<70000 242>,
			<71000 234>,
			<72000 227>,
			<73000 220>,
			<74000 213>,
			<75000 206>,
			<76000 199>,
			<77000 193>,
			<78000 187>,
			<79000 181>,
			<80000 175>,
			<81000 170>,
			<82000 164>,
			<83000 159>,
			<84000 154>,
			<85000 149>,
			<86000 145>,
			<87000 140>,
			<88000 136>,
			<89000 132>,
			<90000 128>,
			<91000 124>,
			<92000 120>,
			<93000 116>,
			<94000 113>,
			<95000 109>,
			<96000 106>,
			<97000 103>,
			<98000 99>,
			<99000 96>,
			<100000 94>,
			<101000 91>,
			<102000 88>,
			<103000 85>,
			<104000 83>,
			<105000 80>,
			<106000 78>,
			<107000 76>,
			<108000 73>,
			<109000 71>,
			<110000 69>,
			<111000 67>,
			<112000 65>,
			<113000 63>,
			<114000 61>,
			<115000 60>,
			<116000 58>,
			<117000 56>,
			<118000 55>,
			<119000 53>,
			<120000 52>,
			<121000 50>,
			<122000 49>,
			<123000 47>,
			<124000 46>,
			<125000 45>;
	};

	&tboard_thermistor7 {
		compatible = "generic-adc-thermal";
		#thermal-sensor-cells = <0>;
		io-channels = <&mt6373_adc AUXADC_VIN1>;
		io-channel-names = "sensor-channel";
		temperature-lookup-table =
			<(-40000) 1799>,
			<(-39000) 1796>,
			<(-38000) 1792>,
			<(-37000) 1789>,
			<(-36000) 1786>,
			<(-35000) 1782>,
			<(-34000) 1778>,
			<(-33000) 1774>,
			<(-32000) 1769>,
			<(-31000) 1764>,
			<(-30000) 1759>,
			<(-29000) 1754>,
			<(-28000) 1749>,
			<(-27000) 1743>,
			<(-26000) 1737>,
			<(-25000) 1730>,
			<(-24000) 1723>,
			<(-23000) 1716>,
			<(-22000) 1709>,
			<(-21000) 1701>,
			<(-20000) 1692>,
			<(-19000) 1684>,
			<(-18000) 1675>,
			<(-17000) 1665>,
			<(-16000) 1655>,
			<(-15000) 1645>,
			<(-14000) 1634>,
			<(-13000) 1623>,
			<(-12000) 1612>,
			<(-11000) 1600>,
			<(-10000) 1587>,
			<(-9000) 1574>,
			<(-8000) 1561>,
			<(-7000) 1547>,
			<(-6000) 1532>,
			<(-5000) 1518>,
			<(-4000) 1502>,
			<(-3000) 1487>,
			<(-2000) 1471>,
			<(-1000) 1454>,
			<0 1437>,
			<1000 1419>,
			<2000 1402>,
			<3000 1383>,
			<4000 1365>,
			<5000 1346>,
			<6000 1326>,
			<7000 1306>,
			<8000 1286>,
			<9000 1266>,
			<10000 1245>,
			<11000 1225>,
			<12000 1203>,
			<13000 1182>,
			<14000 1161>,
			<15000 1139>,
			<16000 1117>,
			<17000 1095>,
			<18000 1073>,
			<19000 1051>,
			<20000 1029>,
			<21000 1007>,
			<22000 985>,
			<23000 963>,
			<24000 941>,
			<25000 920>,
			<26000 898>,
			<27000 876>,
			<28000 855>,
			<29000 834>,
			<30000 813>,
			<31000 792>,
			<32000 772>,
			<33000 751>,
			<34000 731>,
			<35000 712>,
			<36000 692>,
			<37000 673>,
			<38000 655>,
			<39000 636>,
			<40000 618>,
			<41000 601>,
			<42000 583>,
			<43000 566>,
			<44000 550>,
			<45000 534>,
			<46000 518>,
			<47000 502>,
			<48000 487>,
			<49000 472>,
			<50000 458>,
			<51000 444>,
			<52000 430>,
			<53000 417>,
			<54000 404>,
			<55000 392>,
			<56000 380>,
			<57000 368>,
			<58000 356>,
			<59000 345>,
			<60000 334>,
			<61000 324>,
			<62000 313>,
			<63000 303>,
			<64000 294>,
			<65000 284>,
			<66000 275>,
			<67000 267>,
			<68000 258>,
			<69000 250>,
			<70000 242>,
			<71000 234>,
			<72000 227>,
			<73000 220>,
			<74000 213>,
			<75000 206>,
			<76000 199>,
			<77000 193>,
			<78000 187>,
			<79000 181>,
			<80000 175>,
			<81000 170>,
			<82000 164>,
			<83000 159>,
			<84000 154>,
			<85000 149>,
			<86000 145>,
			<87000 140>,
			<88000 136>,
			<89000 132>,
			<90000 128>,
			<91000 124>,
			<92000 120>,
			<93000 116>,
			<94000 113>,
			<95000 109>,
			<96000 106>,
			<97000 103>,
			<98000 99>,
			<99000 96>,
			<100000 94>,
			<101000 91>,
			<102000 88>,
			<103000 85>,
			<104000 83>,
			<105000 80>,
			<106000 78>,
			<107000 76>,
			<108000 73>,
			<109000 71>,
			<110000 69>,
			<111000 67>,
			<112000 65>,
			<113000 63>,
			<114000 61>,
			<115000 60>,
			<116000 58>,
			<117000 56>,
			<118000 55>,
			<119000 53>,
			<120000 52>,
			<121000 50>,
			<122000 49>,
			<123000 47>,
			<124000 46>,
			<125000 45>;
	};

	&tboard_thermistor8 {
		compatible = "generic-adc-thermal";
		#thermal-sensor-cells = <0>;
		io-channels = <&mt6373_adc AUXADC_VIN2>;
		io-channel-names = "sensor-channel";
		temperature-lookup-table =
			<(-40000) 1799>,
			<(-39000) 1796>,
			<(-38000) 1792>,
			<(-37000) 1789>,
			<(-36000) 1786>,
			<(-35000) 1782>,
			<(-34000) 1778>,
			<(-33000) 1774>,
			<(-32000) 1769>,
			<(-31000) 1764>,
			<(-30000) 1759>,
			<(-29000) 1754>,
			<(-28000) 1749>,
			<(-27000) 1743>,
			<(-26000) 1737>,
			<(-25000) 1730>,
			<(-24000) 1723>,
			<(-23000) 1716>,
			<(-22000) 1709>,
			<(-21000) 1701>,
			<(-20000) 1692>,
			<(-19000) 1684>,
			<(-18000) 1675>,
			<(-17000) 1665>,
			<(-16000) 1655>,
			<(-15000) 1645>,
			<(-14000) 1634>,
			<(-13000) 1623>,
			<(-12000) 1612>,
			<(-11000) 1600>,
			<(-10000) 1587>,
			<(-9000) 1574>,
			<(-8000) 1561>,
			<(-7000) 1547>,
			<(-6000) 1532>,
			<(-5000) 1518>,
			<(-4000) 1502>,
			<(-3000) 1487>,
			<(-2000) 1471>,
			<(-1000) 1454>,
			<0 1437>,
			<1000 1419>,
			<2000 1402>,
			<3000 1383>,
			<4000 1365>,
			<5000 1346>,
			<6000 1326>,
			<7000 1306>,
			<8000 1286>,
			<9000 1266>,
			<10000 1245>,
			<11000 1225>,
			<12000 1203>,
			<13000 1182>,
			<14000 1161>,
			<15000 1139>,
			<16000 1117>,
			<17000 1095>,
			<18000 1073>,
			<19000 1051>,
			<20000 1029>,
			<21000 1007>,
			<22000 985>,
			<23000 963>,
			<24000 941>,
			<25000 920>,
			<26000 898>,
			<27000 876>,
			<28000 855>,
			<29000 834>,
			<30000 813>,
			<31000 792>,
			<32000 772>,
			<33000 751>,
			<34000 731>,
			<35000 712>,
			<36000 692>,
			<37000 673>,
			<38000 655>,
			<39000 636>,
			<40000 618>,
			<41000 601>,
			<42000 583>,
			<43000 566>,
			<44000 550>,
			<45000 534>,
			<46000 518>,
			<47000 502>,
			<48000 487>,
			<49000 472>,
			<50000 458>,
			<51000 444>,
			<52000 430>,
			<53000 417>,
			<54000 404>,
			<55000 392>,
			<56000 380>,
			<57000 368>,
			<58000 356>,
			<59000 345>,
			<60000 334>,
			<61000 324>,
			<62000 313>,
			<63000 303>,
			<64000 294>,
			<65000 284>,
			<66000 275>,
			<67000 267>,
			<68000 258>,
			<69000 250>,
			<70000 242>,
			<71000 234>,
			<72000 227>,
			<73000 220>,
			<74000 213>,
			<75000 206>,
			<76000 199>,
			<77000 193>,
			<78000 187>,
			<79000 181>,
			<80000 175>,
			<81000 170>,
			<82000 164>,
			<83000 159>,
			<84000 154>,
			<85000 149>,
			<86000 145>,
			<87000 140>,
			<88000 136>,
			<89000 132>,
			<90000 128>,
			<91000 124>,
			<92000 120>,
			<93000 116>,
			<94000 113>,
			<95000 109>,
			<96000 106>,
			<97000 103>,
			<98000 99>,
			<99000 96>,
			<100000 94>,
			<101000 91>,
			<102000 88>,
			<103000 85>,
			<104000 83>,
			<105000 80>,
			<106000 78>,
			<107000 76>,
			<108000 73>,
			<109000 71>,
			<110000 69>,
			<111000 67>,
			<112000 65>,
			<113000 63>,
			<114000 61>,
			<115000 60>,
			<116000 58>,
			<117000 56>,
			<118000 55>,
			<119000 53>,
			<120000 52>,
			<121000 50>,
			<122000 49>,
			<123000 47>,
			<124000 46>,
			<125000 45>;
	};

	&tboard_thermistor9 {
		compatible = "generic-adc-thermal";
		#thermal-sensor-cells = <0>;
		io-channels = <&mt6373_adc AUXADC_VIN4>;
		io-channel-names = "sensor-channel";
		temperature-lookup-table =
			<(-40000) 1799>,
			<(-39000) 1796>,
			<(-38000) 1792>,
			<(-37000) 1789>,
			<(-36000) 1786>,
			<(-35000) 1782>,
			<(-34000) 1778>,
			<(-33000) 1774>,
			<(-32000) 1769>,
			<(-31000) 1764>,
			<(-30000) 1759>,
			<(-29000) 1754>,
			<(-28000) 1749>,
			<(-27000) 1743>,
			<(-26000) 1737>,
			<(-25000) 1730>,
			<(-24000) 1723>,
			<(-23000) 1716>,
			<(-22000) 1709>,
			<(-21000) 1701>,
			<(-20000) 1692>,
			<(-19000) 1684>,
			<(-18000) 1675>,
			<(-17000) 1665>,
			<(-16000) 1655>,
			<(-15000) 1645>,
			<(-14000) 1634>,
			<(-13000) 1623>,
			<(-12000) 1612>,
			<(-11000) 1600>,
			<(-10000) 1587>,
			<(-9000) 1574>,
			<(-8000) 1561>,
			<(-7000) 1547>,
			<(-6000) 1532>,
			<(-5000) 1518>,
			<(-4000) 1502>,
			<(-3000) 1487>,
			<(-2000) 1471>,
			<(-1000) 1454>,
			<0 1437>,
			<1000 1419>,
			<2000 1402>,
			<3000 1383>,
			<4000 1365>,
			<5000 1346>,
			<6000 1326>,
			<7000 1306>,
			<8000 1286>,
			<9000 1266>,
			<10000 1245>,
			<11000 1225>,
			<12000 1203>,
			<13000 1182>,
			<14000 1161>,
			<15000 1139>,
			<16000 1117>,
			<17000 1095>,
			<18000 1073>,
			<19000 1051>,
			<20000 1029>,
			<21000 1007>,
			<22000 985>,
			<23000 963>,
			<24000 941>,
			<25000 920>,
			<26000 898>,
			<27000 876>,
			<28000 855>,
			<29000 834>,
			<30000 813>,
			<31000 792>,
			<32000 772>,
			<33000 751>,
			<34000 731>,
			<35000 712>,
			<36000 692>,
			<37000 673>,
			<38000 655>,
			<39000 636>,
			<40000 618>,
			<41000 601>,
			<42000 583>,
			<43000 566>,
			<44000 550>,
			<45000 534>,
			<46000 518>,
			<47000 502>,
			<48000 487>,
			<49000 472>,
			<50000 458>,
			<51000 444>,
			<52000 430>,
			<53000 417>,
			<54000 404>,
			<55000 392>,
			<56000 380>,
			<57000 368>,
			<58000 356>,
			<59000 345>,
			<60000 334>,
			<61000 324>,
			<62000 313>,
			<63000 303>,
			<64000 294>,
			<65000 284>,
			<66000 275>,
			<67000 267>,
			<68000 258>,
			<69000 250>,
			<70000 242>,
			<71000 234>,
			<72000 227>,
			<73000 220>,
			<74000 213>,
			<75000 206>,
			<76000 199>,
			<77000 193>,
			<78000 187>,
			<79000 181>,
			<80000 175>,
			<81000 170>,
			<82000 164>,
			<83000 159>,
			<84000 154>,
			<85000 149>,
			<86000 145>,
			<87000 140>,
			<88000 136>,
			<89000 132>,
			<90000 128>,
			<91000 124>,
			<92000 120>,
			<93000 116>,
			<94000 113>,
			<95000 109>,
			<96000 106>,
			<97000 103>,
			<98000 99>,
			<99000 96>,
			<100000 94>,
			<101000 91>,
			<102000 88>,
			<103000 85>,
			<104000 83>,
			<105000 80>,
			<106000 78>,
			<107000 76>,
			<108000 73>,
			<109000 71>,
			<110000 69>,
			<111000 67>,
			<112000 65>,
			<113000 63>,
			<114000 61>,
			<115000 60>,
			<116000 58>,
			<117000 56>,
			<118000 55>,
			<119000 53>,
			<120000 52>,
			<121000 50>,
			<122000 49>,
			<123000 47>,
			<124000 46>,
			<125000 45>;
	};

	&tboard_thermistor10 {
		compatible = "generic-adc-thermal";
		#thermal-sensor-cells = <0>;
		io-channels = <&mt6373_adc AUXADC_VIN5>;
		io-channel-names = "sensor-channel";
		temperature-lookup-table =
			<(-40000) 1799>,
			<(-39000) 1796>,
			<(-38000) 1792>,
			<(-37000) 1789>,
			<(-36000) 1786>,
			<(-35000) 1782>,
			<(-34000) 1778>,
			<(-33000) 1774>,
			<(-32000) 1769>,
			<(-31000) 1764>,
			<(-30000) 1759>,
			<(-29000) 1754>,
			<(-28000) 1749>,
			<(-27000) 1743>,
			<(-26000) 1737>,
			<(-25000) 1730>,
			<(-24000) 1723>,
			<(-23000) 1716>,
			<(-22000) 1709>,
			<(-21000) 1701>,
			<(-20000) 1692>,
			<(-19000) 1684>,
			<(-18000) 1675>,
			<(-17000) 1665>,
			<(-16000) 1655>,
			<(-15000) 1645>,
			<(-14000) 1634>,
			<(-13000) 1623>,
			<(-12000) 1612>,
			<(-11000) 1600>,
			<(-10000) 1587>,
			<(-9000) 1574>,
			<(-8000) 1561>,
			<(-7000) 1547>,
			<(-6000) 1532>,
			<(-5000) 1518>,
			<(-4000) 1502>,
			<(-3000) 1487>,
			<(-2000) 1471>,
			<(-1000) 1454>,
			<0 1437>,
			<1000 1419>,
			<2000 1402>,
			<3000 1383>,
			<4000 1365>,
			<5000 1346>,
			<6000 1326>,
			<7000 1306>,
			<8000 1286>,
			<9000 1266>,
			<10000 1245>,
			<11000 1225>,
			<12000 1203>,
			<13000 1182>,
			<14000 1161>,
			<15000 1139>,
			<16000 1117>,
			<17000 1095>,
			<18000 1073>,
			<19000 1051>,
			<20000 1029>,
			<21000 1007>,
			<22000 985>,
			<23000 963>,
			<24000 941>,
			<25000 920>,
			<26000 898>,
			<27000 876>,
			<28000 855>,
			<29000 834>,
			<30000 813>,
			<31000 792>,
			<32000 772>,
			<33000 751>,
			<34000 731>,
			<35000 712>,
			<36000 692>,
			<37000 673>,
			<38000 655>,
			<39000 636>,
			<40000 618>,
			<41000 601>,
			<42000 583>,
			<43000 566>,
			<44000 550>,
			<45000 534>,
			<46000 518>,
			<47000 502>,
			<48000 487>,
			<49000 472>,
			<50000 458>,
			<51000 444>,
			<52000 430>,
			<53000 417>,
			<54000 404>,
			<55000 392>,
			<56000 380>,
			<57000 368>,
			<58000 356>,
			<59000 345>,
			<60000 334>,
			<61000 324>,
			<62000 313>,
			<63000 303>,
			<64000 294>,
			<65000 284>,
			<66000 275>,
			<67000 267>,
			<68000 258>,
			<69000 250>,
			<70000 242>,
			<71000 234>,
			<72000 227>,
			<73000 220>,
			<74000 213>,
			<75000 206>,
			<76000 199>,
			<77000 193>,
			<78000 187>,
			<79000 181>,
			<80000 175>,
			<81000 170>,
			<82000 164>,
			<83000 159>,
			<84000 154>,
			<85000 149>,
			<86000 145>,
			<87000 140>,
			<88000 136>,
			<89000 132>,
			<90000 128>,
			<91000 124>,
			<92000 120>,
			<93000 116>,
			<94000 113>,
			<95000 109>,
			<96000 106>,
			<97000 103>,
			<98000 99>,
			<99000 96>,
			<100000 94>,
			<101000 91>,
			<102000 88>,
			<103000 85>,
			<104000 83>,
			<105000 80>,
			<106000 78>,
			<107000 76>,
			<108000 73>,
			<109000 71>,
			<110000 69>,
			<111000 67>,
			<112000 65>,
			<113000 63>,
			<114000 61>,
			<115000 60>,
			<116000 58>,
			<117000 56>,
			<118000 55>,
			<119000 53>,
			<120000 52>,
			<121000 50>,
			<122000 49>,
			<123000 47>,
			<124000 46>,
			<125000 45>;
	};

	&thermal_zones {
		conn_therm2: conn_therm2 {
			polling-delay = <0>; /* milliseconds */
			polling-delay-passive = <0>; /* milliseconds */
			thermal-sensors = <&tboard_thermistor4>;

			trips {
				conn_therm2_crit: conn-therm2-crit {
					temperature = <118800>;
					hysteresis = <2000>;
					type = "passive";
				};
			};
		};
		display_therm: display_therm {
			polling-delay = <0>; /* milliseconds */
			polling-delay-passive = <0>; /* milliseconds */
			thermal-sensors = <&tboard_thermistor5>;

			trips {
				display_therm_crit: display-therm-crit {
					temperature = <118800>;
					hysteresis = <2000>;
					type = "passive";
				};
			};
		};
		conn_therm: conn_therm {
			polling-delay = <0>; /* milliseconds */
			polling-delay-passive = <0>; /* milliseconds */
			thermal-sensors = <&tboard_thermistor6>;

			trips {
				conn_therm_crit: conn-therm-crit {
					temperature = <118800>;
					hysteresis = <2000>;
					type = "passive";
				};
			};
		};
		quiet_therm: quiet_therm {
			polling-delay = <0>; /* milliseconds */
			polling-delay-passive = <0>; /* milliseconds */
			thermal-sensors = <&tboard_thermistor7>;

			trips {
				quiet_therm_crit: quiet-therm-crit {
					temperature = <118800>;
					hysteresis = <2000>;
					type = "passive";
				};
			};
		};
		charger_therm1: charger_therm1 {
			polling-delay = <0>; /* milliseconds */
			polling-delay-passive = <0>; /* milliseconds */
			thermal-sensors = <&tboard_thermistor8>;

			trips {
				charger_therm1_crit: charger-therm1-crit {
					temperature = <118800>;
					hysteresis = <2000>;
					type = "passive";
				};
			};
		};
		wifi_therm: wifi_therm {
			polling-delay = <0>; /* milliseconds */
			polling-delay-passive = <0>; /* milliseconds */
			thermal-sensors = <&tboard_thermistor9>;

			trips {
				wifi_therm_crit: wifi-therm-crit {
					temperature = <118800>;
					hysteresis = <2000>;
					type = "passive";
				};
			};
		};
		flash_therm: flash_therm {
			polling-delay = <0>; /* milliseconds */
			polling-delay-passive = <0>; /* milliseconds */
			thermal-sensors = <&tboard_thermistor10>;

			trips {
				flash_therm_crit: flash-therm-crit {
					temperature = <118800>;
					hysteresis = <2000>;
					type = "passive";
				};
			};
		};
	};

#include "mediatek/xiaomi_dash_mt6991_mitee.dtsi"
